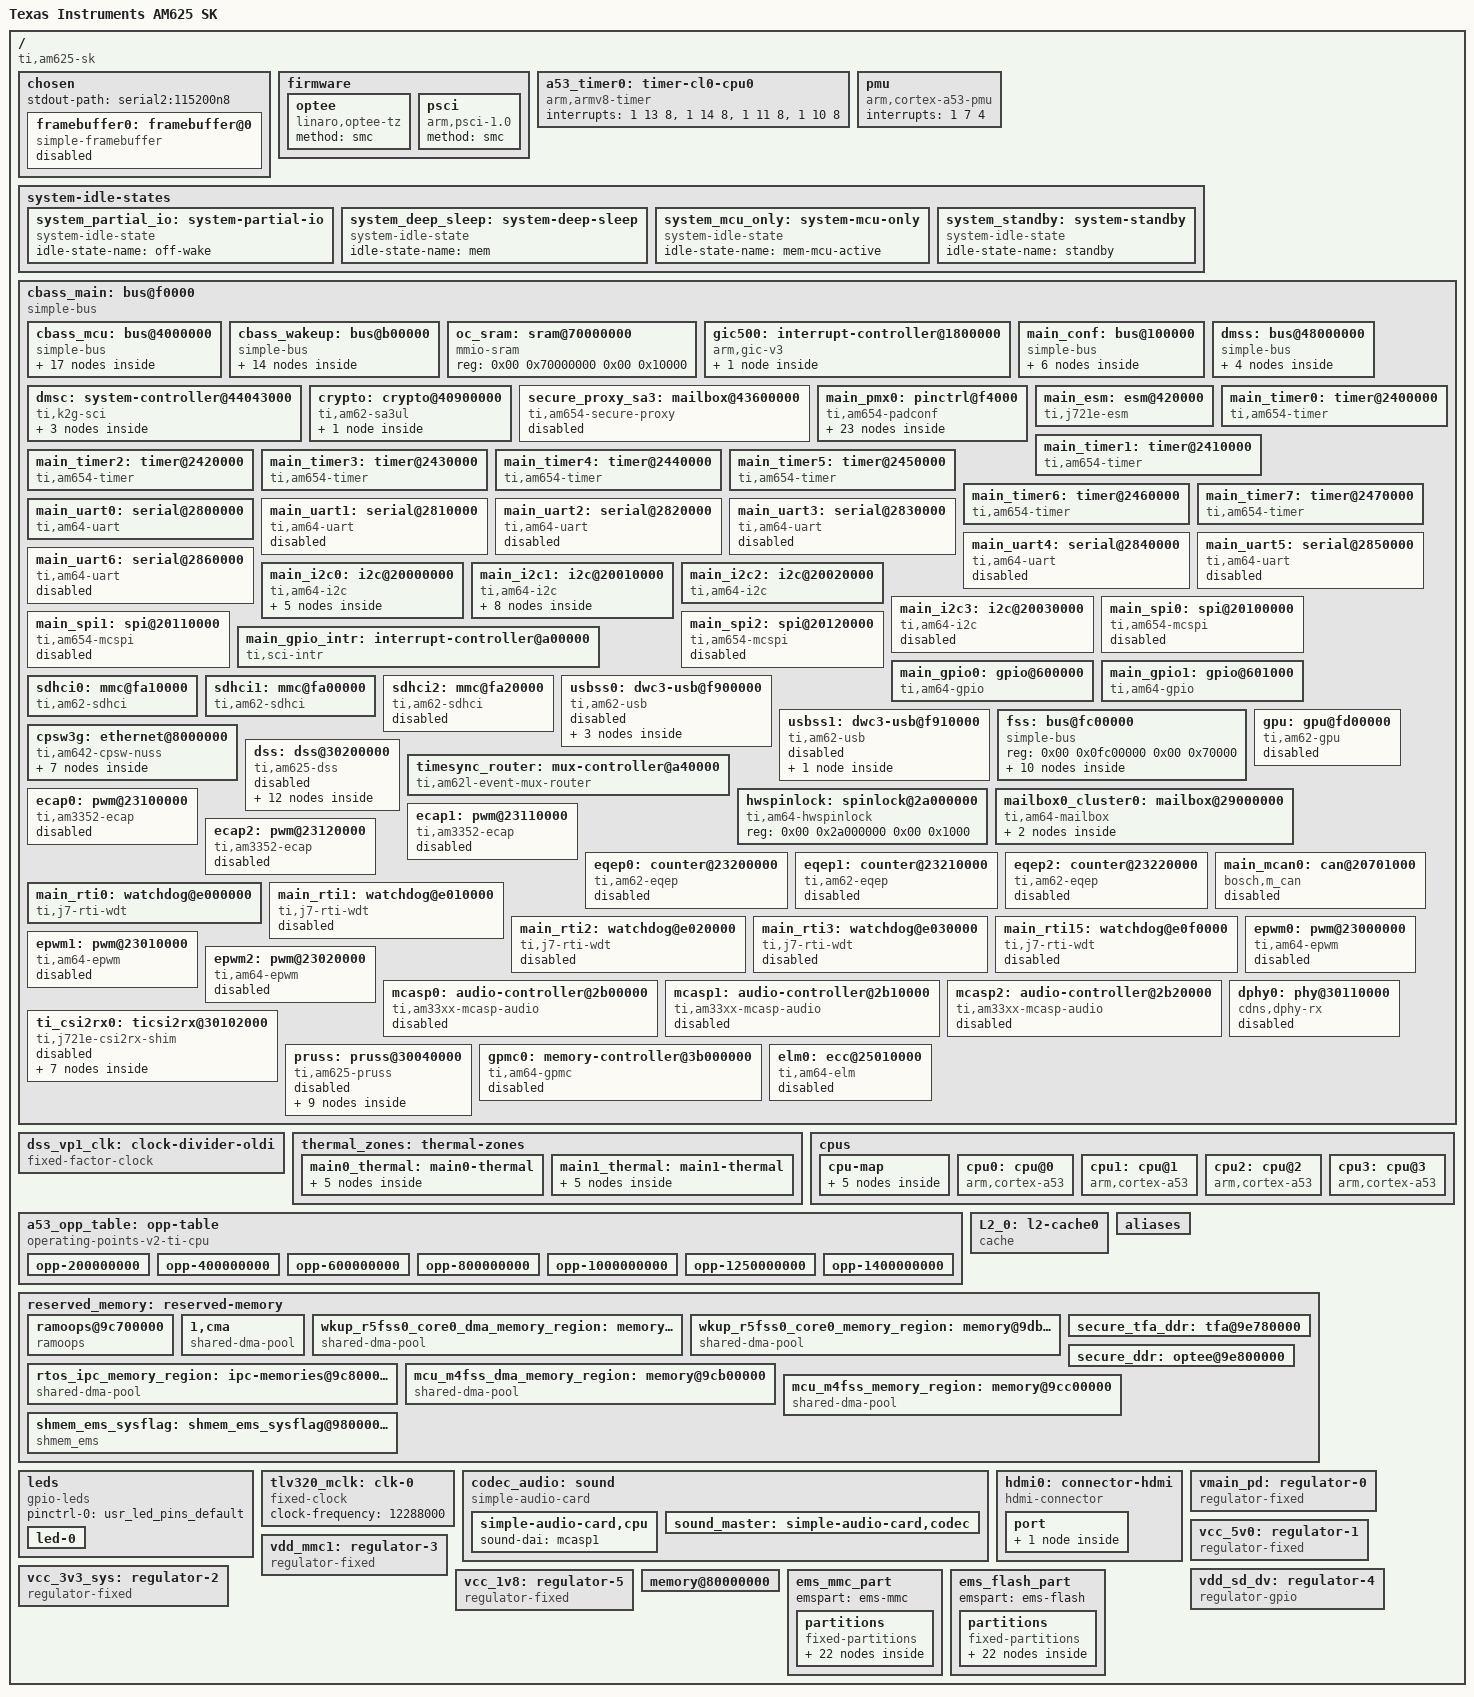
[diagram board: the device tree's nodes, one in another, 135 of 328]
/dts-v1/;
/dts-v1/;
/ {
 model = "Texas Instruments K3 AM625 SoC";
 compatible = "ti,am625";
 interrupt-parent = <&gic500>;
 #address-cells = <2>;
 #size-cells = <2>;
 chosen { };
 firmware {
  optee {
   compatible = "linaro,optee-tz";
   method = "smc";
  };
  psci: psci {
   compatible = "arm,psci-1.0";
   method = "smc";
  };
 };
 a53_timer0: timer-cl0-cpu0 {
  compatible = "arm,armv8-timer";
  interrupts = <1 13 8>,
        <1 14 8>,
        <1 11 8>,
        <1 10 8>;
 };
 pmu: pmu {
  compatible = "arm,cortex-a53-pmu";
  interrupts = <1 7 4>;
 };
 system-idle-states {
  system_partial_io: system-partial-io {
   compatible = "system-idle-state";
   idle-state-name = "off-wake";
  };
  system_deep_sleep: system-deep-sleep {
   compatible = "system-idle-state";
   idle-state-name = "mem";
  };
  system_mcu_only: system-mcu-only {
   compatible = "system-idle-state";
   idle-state-name = "mem-mcu-active";
  };
  system_standby: system-standby {
   compatible = "system-idle-state";
   idle-state-name = "standby";
  };
 };
 cbass_main: bus@f0000 {
  bootph-all;
  compatible = "simple-bus";
  #address-cells = <2>;
  #size-cells = <2>;
  ranges = <0x00 0x000f0000 0x00 0x000f0000 0x00 0x00030000>,
    <0x00 0x00420000 0x00 0x00420000 0x00 0x00001000>,
    <0x00 0x00600000 0x00 0x00600000 0x00 0x00001100>,
    <0x00 0x00703000 0x00 0x00703000 0x00 0x00000200>,
    <0x00 0x0070c000 0x00 0x0070c000 0x00 0x00000200>,
    <0x00 0x00a40000 0x00 0x00a40000 0x00 0x00000800>,
    <0x00 0x01000000 0x00 0x01000000 0x00 0x01b28400>,
    <0x00 0x08000000 0x00 0x08000000 0x00 0x00200000>,
    <0x00 0x0e000000 0x00 0x0e000000 0x00 0x01d20000>,
    <0x00 0x0fd00000 0x00 0x0fd00000 0x00 0x00020000>,
    <0x00 0x20000000 0x00 0x20000000 0x00 0x0a008000>,
    <0x00 0x30040000 0x00 0x30040000 0x00 0x00080000>,
    <0x00 0x30101000 0x00 0x30101000 0x00 0x00010100>,
    <0x00 0x30200000 0x00 0x30200000 0x00 0x00010000>,
    <0x00 0x31000000 0x00 0x31000000 0x00 0x00050000>,
    <0x00 0x31100000 0x00 0x31100000 0x00 0x00050000>,
    <0x00 0x3b000000 0x00 0x3b000000 0x00 0x00000400>,
    <0x00 0x40900000 0x00 0x40900000 0x00 0x00030000>,
    <0x00 0x43600000 0x00 0x43600000 0x00 0x00010000>,
    <0x00 0x44043000 0x00 0x44043000 0x00 0x00000fe0>,
    <0x00 0x44860000 0x00 0x44860000 0x00 0x00040000>,
    <0x00 0x48000000 0x00 0x48000000 0x00 0x06400000>,
    <0x00 0x50000000 0x00 0x50000000 0x00 0x08000000>,
    <0x00 0x60000000 0x00 0x60000000 0x00 0x08000000>,
    <0x00 0x70000000 0x00 0x70000000 0x00 0x00010000>,
    <0x01 0x00000000 0x01 0x00000000 0x00 0x00310000>,
    <0x05 0x00000000 0x05 0x00000000 0x01 0x00000000>,
    <0x00 0x04000000 0x00 0x04000000 0x00 0x01ff1400>,
    <0x00 0x00b00000 0x00 0x00b00000 0x00 0x00002400>,
    <0x00 0x2b000000 0x00 0x2b000000 0x00 0x00300400>,
    <0x00 0x43000000 0x00 0x43000000 0x00 0x00020000>,
    <0x00 0x78000000 0x00 0x78000000 0x00 0x00008000>,
    <0x00 0x78100000 0x00 0x78100000 0x00 0x00008000>;
  cbass_mcu: bus@4000000 {
   bootph-all;
   compatible = "simple-bus";
   #address-cells = <2>;
   #size-cells = <2>;
   ranges = <0x00 0x04000000 0x00 0x04000000 0x00 0x01ff1400>;
  };
  cbass_wakeup: bus@b00000 {
   bootph-all;
   compatible = "simple-bus";
   #address-cells = <2>;
   #size-cells = <2>;
   ranges = <0x00 0x00b00000 0x00 0x00b00000 0x00 0x00002400>,
     <0x00 0x2b000000 0x00 0x2b000000 0x00 0x00300400>,
     <0x00 0x43000000 0x00 0x43000000 0x00 0x00020000>,
     <0x00 0x78000000 0x00 0x78000000 0x00 0x00008000>,
     <0x00 0x78100000 0x00 0x78100000 0x00 0x00008000>;
  };
 };
 dss_vp1_clk: clock-divider-oldi {
  compatible = "fixed-factor-clock";
  clocks = <&k3_clks 186 0>;
  #clock-cells = <0>;
  clock-div = <7>;
  clock-mult = <1>;
 };
thermal_zones: thermal-zones {
 main0_thermal: main0-thermal {
  polling-delay-passive = <250>;
  polling-delay = <500>;
  thermal-sensors = <&wkup_vtm0 0>;
  trips {
   main0_alert: main0-alert {
    temperature = <95000>;
    hysteresis = <2000>;
    type = "passive";
   };
   main0_crit: main0-crit {
    temperature = <105000>;
    hysteresis = <2000>;
    type = "critical";
   };
  };
  cooling-maps {
   map0 {
    trip = <&main0_alert>;
    cooling-device =
     <&cpu0 (~0) (~0)>,
     <&cpu1 (~0) (~0)>,
     <&cpu2 (~0) (~0)>,
     <&cpu3 (~0) (~0)>;
   };
  };
 };
 main1_thermal: main1-thermal {
  polling-delay-passive = <250>;
  polling-delay = <500>;
  thermal-sensors = <&wkup_vtm0 1>;
  trips {
   main1_alert: main1-alert {
    temperature = <95000>;
    hysteresis = <2000>;
    type = "passive";
   };
   main1_crit: main1-crit {
    temperature = <105000>;
    hysteresis = <2000>;
    type = "critical";
   };
  };
  cooling-maps {
   map0 {
    trip = <&main1_alert>;
    cooling-device =
     <&cpu0 (~0) (~0)>,
     <&cpu1 (~0) (~0)>,
     <&cpu2 (~0) (~0)>,
     <&cpu3 (~0) (~0)>;
   };
  };
 };
};
};
&cbass_main {
 oc_sram: sram@70000000 {
  compatible = "mmio-sram";
  reg = <0x00 0x70000000 0x00 0x10000>;
  #address-cells = <1>;
  #size-cells = <1>;
  ranges = <0x0 0x00 0x70000000 0x10000>;
 };
 gic500: interrupt-controller@1800000 {
  compatible = "arm,gic-v3";
  #address-cells = <2>;
  #size-cells = <2>;
  ranges;
  #interrupt-cells = <3>;
  interrupt-controller;
  reg = <0x00 0x01800000 0x00 0x10000>,
        <0x00 0x01880000 0x00 0xc0000>,
        <0x01 0x00000000 0x00 0x2000>,
        <0x01 0x00010000 0x00 0x1000>,
        <0x01 0x00020000 0x00 0x2000>;
  interrupts = <1 9 4>;
  gic_its: msi-controller@1820000 {
   compatible = "arm,gic-v3-its";
   reg = <0x00 0x01820000 0x00 0x10000>;
   socionext,synquacer-pre-its = <0x1000000 0x400000>;
   msi-controller;
   #msi-cells = <1>;
  };
 };
 main_conf: bus@100000 {
  compatible = "simple-bus";
  #address-cells = <1>;
  #size-cells = <1>;
  ranges = <0x0 0x00 0x00100000 0x20000>;
  phy_gmii_sel: phy@4044 {
   compatible = "ti,am654-phy-gmii-sel";
   reg = <0x4044 0x8>;
   #phy-cells = <1>;
  };
  epwm_tbclk: clock-controller@4130 {
   compatible = "ti,am62-epwm-tbclk";
   reg = <0x4130 0x4>;
   #clock-cells = <1>;
  };
  audio_refclk0: clock-controller@82e0 {
   compatible = "ti,am62-audio-refclk";
   reg = <0x82e0 0x4>;
   clocks = <&k3_clks 157 0>;
   assigned-clocks = <&k3_clks 157 0>;
   assigned-clock-parents = <&k3_clks 157 8>;
   #clock-cells = <0>;
  };
  audio_refclk1: clock-controller@82e4 {
   compatible = "ti,am62-audio-refclk";
   reg = <0x82e4 0x4>;
   clocks = <&k3_clks 157 10>;
   assigned-clocks = <&k3_clks 157 10>;
   assigned-clock-parents = <&k3_clks 157 18>;
   #clock-cells = <0>;
  };
  dss_oldi_io_ctrl: oldi-io-controller@8600 {
   compatible = "ti,am625-dss-oldi-io-ctrl", "syscon";
   reg = <0x8600 0x200>;
  };
  dss_clk_ctrl: dss_clk_ctrl@8300 {
   compatible = "ti,am625-dss-clk-ctrl", "syscon";
   reg = <0x8300 0x4>;
  };
 };
 dmss: bus@48000000 {
  bootph-all;
  compatible = "simple-bus";
  #address-cells = <2>;
  #size-cells = <2>;
  dma-ranges;
  ranges = <0x00 0x48000000 0x00 0x48000000 0x00 0x06400000>;
  ti,sci-dev-id = <25>;
  secure_proxy_main: mailbox@4d000000 {
   bootph-all;
   compatible = "ti,am654-secure-proxy";
   #mbox-cells = <1>;
   reg-names = "target_data", "rt", "scfg";
   reg = <0x00 0x4d000000 0x00 0x80000>,
         <0x00 0x4a600000 0x00 0x80000>,
         <0x00 0x4a400000 0x00 0x80000>;
   interrupt-names = "rx_012";
   interrupts = <0 34 4>;
  };
  inta_main_dmss: interrupt-controller@48000000 {
   compatible = "ti,sci-inta";
   reg = <0x00 0x48000000 0x00 0x100000>;
   #interrupt-cells = <0>;
   interrupt-controller;
   interrupt-parent = <&gic500>;
   msi-controller;
   ti,sci = <&dmsc>;
   ti,sci-dev-id = <28>;
   ti,interrupt-ranges = <4 68 36>;
   ti,unmapped-event-sources = <&main_bcdma>, <&main_pktdma>;
  };
  main_bcdma: dma-controller@485c0100 {
   compatible = "ti,am64-dmss-bcdma";
   reg = <0x00 0x485c0100 0x00 0x100>,
         <0x00 0x4c000000 0x00 0x20000>,
         <0x00 0x4a820000 0x00 0x20000>,
         <0x00 0x4aa40000 0x00 0x20000>,
         <0x00 0x4bc00000 0x00 0x100000>,
         <0x00 0x48600000 0x00 0x8000>,
         <0x00 0x484a4000 0x00 0x2000>,
         <0x00 0x484c2000 0x00 0x2000>,
         <0x00 0x48420000 0x00 0x2000>;
   reg-names = "gcfg", "bchanrt", "rchanrt", "tchanrt", "ringrt",
        "ring", "tchan", "rchan", "bchan";
   msi-parent = <&inta_main_dmss>;
   #dma-cells = <3>;
   ti,sci = <&dmsc>;
   ti,sci-dev-id = <26>;
   ti,sci-rm-range-bchan = <0x20>;
   ti,sci-rm-range-rchan = <0x21>;
   ti,sci-rm-range-tchan = <0x22>;
  };
  main_pktdma: dma-controller@485c0000 {
   compatible = "ti,am64-dmss-pktdma";
   reg = <0x00 0x485c0000 0x00 0x100>,
         <0x00 0x4a800000 0x00 0x20000>,
         <0x00 0x4aa00000 0x00 0x20000>,
         <0x00 0x4b800000 0x00 0x200000>,
         <0x00 0x485e0000 0x00 0x10000>,
         <0x00 0x484a0000 0x00 0x2000>,
         <0x00 0x484c0000 0x00 0x2000>,
         <0x00 0x48430000 0x00 0x1000>;
   reg-names = "gcfg", "rchanrt", "tchanrt", "ringrt",
        "ring", "tchan", "rchan", "rflow";
   msi-parent = <&inta_main_dmss>;
   #dma-cells = <2>;
   ti,sci = <&dmsc>;
   ti,sci-dev-id = <30>;
   ti,sci-rm-range-tchan = <0x23>,
      <0x24>,
      <0x25>,
      <0x26>;
   ti,sci-rm-range-tflow = <0x10>,
      <0x11>,
      <0x12>,
      <0x13>;
   ti,sci-rm-range-rchan = <0x29>,
      <0x2b>,
      <0x2d>,
      <0x2f>,
      <0x31>,
      <0x33>;
   ti,sci-rm-range-rflow = <0x2a>,
      <0x2c>,
      <0x2e>,
      <0x32>;
  };
 };
 dmsc: system-controller@44043000 {
  bootph-all;
  compatible = "ti,k2g-sci";
  ti,host-id = <12>;
  mbox-names = "rx", "tx";
  mboxes = <&secure_proxy_main 12>,
    <&secure_proxy_main 13>;
  reg-names = "debug_messages";
  reg = <0x00 0x44043000 0x00 0xfe0>;
  k3_pds: power-controller {
   bootph-all;
   compatible = "ti,sci-pm-domain";
   #power-domain-cells = <2>;
  };
  k3_clks: clock-controller {
   bootph-all;
   compatible = "ti,k2g-sci-clk";
   #clock-cells = <2>;
  };
  k3_reset: reset-controller {
   bootph-all;
   compatible = "ti,sci-reset";
   #reset-cells = <2>;
  };
 };
 crypto: crypto@40900000 {
  compatible = "ti,am62-sa3ul";
  reg = <0x00 0x40900000 0x00 0x1200>;
  dmas = <&main_pktdma 0xf501 0>, <&main_pktdma 0x7506 0>,
         <&main_pktdma 0x7507 0>;
  dma-names = "tx", "rx1", "rx2";
  #address-cells = <2>;
  #size-cells = <2>;
  ranges = <0x00 0x40900000 0x00 0x40900000 0x00 0x30000>;
  rng: rng@40910000 {
   compatible = "inside-secure,safexcel-eip76";
   reg = <0x00 0x40910000 0x00 0x7d>;
   interrupts = <0 129 4>;
   status = "reserved";
  };
 };
 secure_proxy_sa3: mailbox@43600000 {
  bootph-pre-ram;
  compatible = "ti,am654-secure-proxy";
  #mbox-cells = <1>;
  reg-names = "target_data", "rt", "scfg";
  reg = <0x00 0x43600000 0x00 0x10000>,
        <0x00 0x44880000 0x00 0x20000>,
        <0x00 0x44860000 0x00 0x20000>;
  status = "disabled";
 };
 main_pmx0: pinctrl@f4000 {
  bootph-all;
  compatible = "ti,am654-padconf", "pinctrl-single";
  reg = <0x00 0xf4000 0x00 0x2ac>;
  #pinctrl-cells = <1>;
  pinctrl-single,register-width = <32>;
  pinctrl-single,function-mask = <0xffffffff>;
  interrupts = <0 98 4>;
  interrupt-controller;
  #interrupt-cells = <1>;
 };
 main_esm: esm@420000 {
  bootph-pre-ram;
  compatible = "ti,j721e-esm";
  reg = <0x00 0x420000 0x00 0x1000>;
  ti,esm-pins = <160>, <161>, <162>, <163>, <177>, <178>;
 };
 main_timer0: timer@2400000 {
  bootph-all;
  compatible = "ti,am654-timer";
  reg = <0x00 0x2400000 0x00 0x400>;
  interrupts = <0 120 4>;
  clocks = <&k3_clks 36 2>;
  clock-names = "fck";
  assigned-clocks = <&k3_clks 36 2>;
  assigned-clock-parents = <&k3_clks 36 3>;
  power-domains = <&k3_pds 36 1>;
  ti,timer-pwm;
 };
 main_timer1: timer@2410000 {
  compatible = "ti,am654-timer";
  reg = <0x00 0x2410000 0x00 0x400>;
  interrupts = <0 121 4>;
  clocks = <&k3_clks 37 2>;
  clock-names = "fck";
  assigned-clocks = <&k3_clks 37 2>;
  assigned-clock-parents = <&k3_clks 37 3>;
  power-domains = <&k3_pds 37 1>;
  ti,timer-pwm;
 };
 main_timer2: timer@2420000 {
  compatible = "ti,am654-timer";
  reg = <0x00 0x2420000 0x00 0x400>;
  interrupts = <0 122 4>;
  clocks = <&k3_clks 38 2>;
  clock-names = "fck";
  assigned-clocks = <&k3_clks 38 2>;
  assigned-clock-parents = <&k3_clks 38 3>;
  power-domains = <&k3_pds 38 1>;
  ti,timer-pwm;
 };
 main_timer3: timer@2430000 {
  compatible = "ti,am654-timer";
  reg = <0x00 0x2430000 0x00 0x400>;
  interrupts = <0 123 4>;
  clocks = <&k3_clks 39 2>;
  clock-names = "fck";
  assigned-clocks = <&k3_clks 39 2>;
  assigned-clock-parents = <&k3_clks 39 3>;
  power-domains = <&k3_pds 39 1>;
  ti,timer-pwm;
 };
 main_timer4: timer@2440000 {
  compatible = "ti,am654-timer";
  reg = <0x00 0x2440000 0x00 0x400>;
  interrupts = <0 124 4>;
  clocks = <&k3_clks 40 2>;
  clock-names = "fck";
  assigned-clocks = <&k3_clks 40 2>;
  assigned-clock-parents = <&k3_clks 40 3>;
  power-domains = <&k3_pds 40 1>;
  ti,timer-pwm;
 };
 main_timer5: timer@2450000 {
  compatible = "ti,am654-timer";
  reg = <0x00 0x2450000 0x00 0x400>;
  interrupts = <0 125 4>;
  clocks = <&k3_clks 41 2>;
  clock-names = "fck";
  assigned-clocks = <&k3_clks 41 2>;
  assigned-clock-parents = <&k3_clks 41 3>;
  power-domains = <&k3_pds 41 1>;
  ti,timer-pwm;
 };
 main_timer6: timer@2460000 {
  compatible = "ti,am654-timer";
  reg = <0x00 0x2460000 0x00 0x400>;
  interrupts = <0 126 4>;
  clocks = <&k3_clks 42 2>;
  clock-names = "fck";
  assigned-clocks = <&k3_clks 42 2>;
  assigned-clock-parents = <&k3_clks 42 3>;
  power-domains = <&k3_pds 42 1>;
  ti,timer-pwm;
 };
 main_timer7: timer@2470000 {
  compatible = "ti,am654-timer";
  reg = <0x00 0x2470000 0x00 0x400>;
  interrupts = <0 127 4>;
  clocks = <&k3_clks 43 2>;
  clock-names = "fck";
  assigned-clocks = <&k3_clks 43 2>;
  assigned-clock-parents = <&k3_clks 43 3>;
  power-domains = <&k3_pds 43 1>;
  ti,timer-pwm;
 };
 main_uart0: serial@2800000 {
  compatible = "ti,am64-uart", "ti,am654-uart";
  reg = <0x00 0x02800000 0x00 0x100>;
  interrupts = <0 178 4>;
  power-domains = <&k3_pds 146 1>;
  clocks = <&k3_clks 146 0>;
  clock-names = "fclk";
  status = "disabled";
 };
 main_uart1: serial@2810000 {
  compatible = "ti,am64-uart", "ti,am654-uart";
  reg = <0x00 0x02810000 0x00 0x100>;
  interrupts = <0 179 4>;
  power-domains = <&k3_pds 152 1>;
  clocks = <&k3_clks 152 0>;
  clock-names = "fclk";
  status = "disabled";
 };
 main_uart2: serial@2820000 {
  compatible = "ti,am64-uart", "ti,am654-uart";
  reg = <0x00 0x02820000 0x00 0x100>;
  interrupts = <0 180 4>;
  power-domains = <&k3_pds 153 1>;
  clocks = <&k3_clks 153 0>;
  clock-names = "fclk";
  status = "disabled";
 };
 main_uart3: serial@2830000 {
  compatible = "ti,am64-uart", "ti,am654-uart";
  reg = <0x00 0x02830000 0x00 0x100>;
  interrupts = <0 181 4>;
  power-domains = <&k3_pds 154 1>;
  clocks = <&k3_clks 154 0>;
  clock-names = "fclk";
  status = "disabled";
 };
 main_uart4: serial@2840000 {
  compatible = "ti,am64-uart", "ti,am654-uart";
  reg = <0x00 0x02840000 0x00 0x100>;
  interrupts = <0 182 4>;
  power-domains = <&k3_pds 155 1>;
  clocks = <&k3_clks 155 0>;
  clock-names = "fclk";
  status = "disabled";
 };
 main_uart5: serial@2850000 {
  compatible = "ti,am64-uart", "ti,am654-uart";
  reg = <0x00 0x02850000 0x00 0x100>;
  interrupts = <0 183 4>;
  power-domains = <&k3_pds 156 1>;
  clocks = <&k3_clks 156 0>;
  clock-names = "fclk";
  status = "disabled";
 };
 main_uart6: serial@2860000 {
  compatible = "ti,am64-uart", "ti,am654-uart";
  reg = <0x00 0x02860000 0x00 0x100>;
  interrupts = <0 184 4>;
  power-domains = <&k3_pds 158 1>;
  clocks = <&k3_clks 158 0>;
  clock-names = "fclk";
  status = "disabled";
 };
 main_i2c0: i2c@20000000 {
  compatible = "ti,am64-i2c", "ti,omap4-i2c";
  reg = <0x00 0x20000000 0x00 0x100>;
  interrupts = <0 161 4>;
  #address-cells = <1>;
  #size-cells = <0>;
  power-domains = <&k3_pds 102 1>;
  clocks = <&k3_clks 102 2>;
  clock-names = "fck";
  status = "disabled";
 };
 main_i2c1: i2c@20010000 {
  compatible = "ti,am64-i2c", "ti,omap4-i2c";
  reg = <0x00 0x20010000 0x00 0x100>;
  interrupts = <0 162 4>;
  #address-cells = <1>;
  #size-cells = <0>;
  power-domains = <&k3_pds 103 1>;
  clocks = <&k3_clks 103 2>;
  clock-names = "fck";
  status = "disabled";
 };
 main_i2c2: i2c@20020000 {
  compatible = "ti,am64-i2c", "ti,omap4-i2c";
  reg = <0x00 0x20020000 0x00 0x100>;
  interrupts = <0 163 4>;
  #address-cells = <1>;
  #size-cells = <0>;
  power-domains = <&k3_pds 104 1>;
  clocks = <&k3_clks 104 2>;
  clock-names = "fck";
  status = "disabled";
 };
 main_i2c3: i2c@20030000 {
  compatible = "ti,am64-i2c", "ti,omap4-i2c";
  reg = <0x00 0x20030000 0x00 0x100>;
  interrupts = <0 164 4>;
  #address-cells = <1>;
  #size-cells = <0>;
  power-domains = <&k3_pds 105 1>;
  clocks = <&k3_clks 105 2>;
  clock-names = "fck";
  status = "disabled";
 };
 main_spi0: spi@20100000 {
  compatible = "ti,am654-mcspi", "ti,omap4-mcspi";
  reg = <0x00 0x20100000 0x00 0x400>;
  interrupts = <0 172 4>;
  #address-cells = <1>;
  #size-cells = <0>;
  power-domains = <&k3_pds 141 1>;
  clocks = <&k3_clks 141 0>;
  status = "disabled";
 };
 main_spi1: spi@20110000 {
  compatible = "ti,am654-mcspi","ti,omap4-mcspi";
  reg = <0x00 0x20110000 0x00 0x400>;
  interrupts = <0 173 4>;
  #address-cells = <1>;
  #size-cells = <0>;
  power-domains = <&k3_pds 142 1>;
  clocks = <&k3_clks 142 0>;
  status = "disabled";
 };
 main_spi2: spi@20120000 {
  compatible = "ti,am654-mcspi","ti,omap4-mcspi";
  reg = <0x00 0x20120000 0x00 0x400>;
  interrupts = <0 174 4>;
  #address-cells = <1>;
  #size-cells = <0>;
  power-domains = <&k3_pds 143 1>;
  clocks = <&k3_clks 143 0>;
  status = "disabled";
 };
 main_gpio_intr: interrupt-controller@a00000 {
  compatible = "ti,sci-intr";
  reg = <0x00 0x00a00000 0x00 0x800>;
  ti,intr-trigger-type = <1>;
  interrupt-controller;
  interrupt-parent = <&gic500>;
  #interrupt-cells = <1>;
  ti,sci = <&dmsc>;
  ti,sci-dev-id = <3>;
  ti,interrupt-ranges = <0 32 16>;
 };
 main_gpio0: gpio@600000 {
  compatible = "ti,am64-gpio", "ti,keystone-gpio";
  reg = <0x0 0x00600000 0x0 0x100>;
  gpio-ranges = <&main_pmx0 0 0 32>,
         <&main_pmx0 32 33 38>,
         <&main_pmx0 70 72 22>;
  gpio-controller;
  #gpio-cells = <2>;
  interrupt-parent = <&main_gpio_intr>;
  interrupts = <190>, <191>, <192>,
        <193>, <194>, <195>;
  interrupt-controller;
  #interrupt-cells = <2>;
  ti,ngpio = <92>;
  ti,davinci-gpio-unbanked = <0>;
  power-domains = <&k3_pds 77 1>;
  clocks = <&k3_clks 77 0>;
  clock-names = "gpio";
 };
 main_gpio1: gpio@601000 {
  compatible = "ti,am64-gpio", "ti,keystone-gpio";
  reg = <0x0 0x00601000 0x0 0x100>;
  gpio-controller;
  gpio-ranges = <&main_pmx0 0 94 41>,
         <&main_pmx0 41 136 6>,
         <&main_pmx0 47 143 3>,
         <&main_pmx0 50 149 2>;
  #gpio-cells = <2>;
  interrupt-parent = <&main_gpio_intr>;
  interrupts = <180>, <181>, <182>,
        <183>, <184>, <185>;
  interrupt-controller;
  #interrupt-cells = <2>;
  ti,ngpio = <52>;
  ti,davinci-gpio-unbanked = <0>;
  power-domains = <&k3_pds 78 1>;
  clocks = <&k3_clks 78 0>;
  clock-names = "gpio";
 };
 sdhci0: mmc@fa10000 {
  compatible = "ti,am62-sdhci";
  reg = <0x00 0x0fa10000 0x00 0x1000>, <0x00 0x0fa18000 0x00 0x400>;
  interrupts = <0 133 4>;
  power-domains = <&k3_pds 57 1>;
  clocks = <&k3_clks 57 5>, <&k3_clks 57 6>;
  clock-names = "clk_ahb", "clk_xin";
  bus-width = <8>;
  mmc-hs200-1_8v;
  ti,clkbuf-sel = <0x7>;
  ti,otap-del-sel-legacy = <0x0>;
  ti,otap-del-sel-mmc-hs = <0x0>;
  ti,otap-del-sel-hs200 = <0x6>;
  ti,itap-del-sel-legacy = <0x0>;
  ti,itap-del-sel-mmc-hs = <0x0>;
  status = "disabled";
 };
 sdhci1: mmc@fa00000 {
  compatible = "ti,am62-sdhci";
  reg = <0x00 0x0fa00000 0x00 0x1000>, <0x00 0x0fa08000 0x00 0x400>;
  interrupts = <0 83 4>;
  power-domains = <&k3_pds 58 1>;
  clocks = <&k3_clks 58 5>, <&k3_clks 58 6>;
  clock-names = "clk_ahb", "clk_xin";
  bus-width = <4>;
  ti,clkbuf-sel = <0x7>;
  ti,otap-del-sel-legacy = <0x0>;
  ti,otap-del-sel-sd-hs = <0x0>;
  ti,otap-del-sel-sdr12 = <0xf>;
  ti,otap-del-sel-sdr25 = <0xf>;
  ti,otap-del-sel-sdr50 = <0xc>;
  ti,otap-del-sel-sdr104 = <0x6>;
  ti,otap-del-sel-ddr50 = <0x9>;
  ti,itap-del-sel-legacy = <0x0>;
  ti,itap-del-sel-sd-hs = <0x0>;
  ti,itap-del-sel-sdr12 = <0x0>;
  ti,itap-del-sel-sdr25 = <0x0>;
  status = "disabled";
 };
 sdhci2: mmc@fa20000 {
  compatible = "ti,am62-sdhci";
  reg = <0x00 0x0fa20000 0x00 0x1000>, <0x00 0x0fa28000 0x00 0x400>;
  interrupts = <0 82 4>;
  power-domains = <&k3_pds 184 1>;
  clocks = <&k3_clks 184 5>, <&k3_clks 184 6>;
  clock-names = "clk_ahb", "clk_xin";
  bus-width = <4>;
  ti,clkbuf-sel = <0x7>;
  ti,otap-del-sel-legacy = <0x0>;
  ti,otap-del-sel-sd-hs = <0x0>;
  ti,otap-del-sel-sdr12 = <0xf>;
  ti,otap-del-sel-sdr25 = <0xf>;
  ti,otap-del-sel-sdr50 = <0xc>;
  ti,otap-del-sel-sdr104 = <0x6>;
  ti,otap-del-sel-ddr50 = <0x9>;
  ti,itap-del-sel-legacy = <0x0>;
  ti,itap-del-sel-sd-hs = <0x0>;
  ti,itap-del-sel-sdr12 = <0x0>;
  ti,itap-del-sel-sdr25 = <0x0>;
  status = "disabled";
 };
 usbss0: dwc3-usb@f900000 {
  compatible = "ti,am62-usb";
  reg = <0x00 0x0f900000 0x00 0x800>,
        <0x00 0x0f908000 0x00 0x400>;
  clocks = <&k3_clks 161 3>;
  clock-names = "ref";
  ti,syscon-phy-pll-refclk = <&usb0_phy_ctrl 0x0>;
  #address-cells = <2>;
  #size-cells = <2>;
  power-domains = <&k3_pds 178 1>;
  ranges;
  status = "disabled";
  usb0: usb@31000000 {
   compatible = "snps,dwc3";
   reg = <0x00 0x31000000 0x00 0x50000>;
   interrupts = <0 188 4>,
         <0 188 4>;
   interrupt-names = "host", "peripheral";
   maximum-speed = "high-speed";
   dr_mode = "otg";
   snps,usb2-gadget-lpm-disable;
   snps,usb2-lpm-disable;
  };
 };
 usbss1: dwc3-usb@f910000 {
  compatible = "ti,am62-usb";
  reg = <0x00 0x0f910000 0x00 0x800>,
        <0x00 0x0f918000 0x00 0x400>;
  clocks = <&k3_clks 162 3>;
  clock-names = "ref";
  ti,syscon-phy-pll-refclk = <&usb1_phy_ctrl 0x0>;
  #address-cells = <2>;
  #size-cells = <2>;
  power-domains = <&k3_pds 179 1>;
  ranges;
  status = "disabled";
  usb1: usb@31100000 {
   compatible = "snps,dwc3";
   reg = <0x00 0x31100000 0x00 0x50000>;
   interrupts = <0 226 4>,
         <0 226 4>;
   interrupt-names = "host", "peripheral";
   maximum-speed = "high-speed";
   dr_mode = "otg";
   snps,usb2-gadget-lpm-disable;
   snps,usb2-lpm-disable;
  };
 };
 fss: bus@fc00000 {
  compatible = "simple-bus";
  reg = <0x00 0x0fc00000 0x00 0x70000>;
  #address-cells = <2>;
  #size-cells = <2>;
  ranges;
  ospi0: spi@fc40000 {
   compatible = "ti,am654-ospi", "cdns,qspi-nor";
   reg = <0x00 0x0fc40000 0x00 0x100>,
         <0x05 0x00000000 0x01 0x00000000>;
   interrupts = <0 139 4>;
   cdns,fifo-depth = <256>;
   cdns,fifo-width = <4>;
   cdns,trigger-address = <0x0>;
   cdns,phase-detect-selector = <2>;
   clocks = <&k3_clks 75 7>;
   assigned-clocks = <&k3_clks 75 7>;
   assigned-clock-parents = <&k3_clks 75 8>;
   assigned-clock-rates = <166666666>;
   power-domains = <&k3_pds 75 1>;
   #address-cells = <1>;
   #size-cells = <0>;
   status = "disabled";
  };
 };
 gpu: gpu@fd00000 {
  compatible = "ti,am62-gpu", "img,img-axe-1-16m", "img,img-axe",
        "img,img-rogue";
  reg = <0x00 0x0fd00000 0x00 0x20000>;
  clocks = <&k3_clks 187 0>;
  clock-names = "core";
  interrupts = <0 86 4>;
  power-domains = <&k3_pds 187 1>;
  power-domain-names = "a";
 };
 cpsw3g: ethernet@8000000 {
  compatible = "ti,am642-cpsw-nuss";
  #address-cells = <2>;
  #size-cells = <2>;
  reg = <0x00 0x08000000 0x00 0x200000>;
  reg-names = "cpsw_nuss";
  ranges = <0x00 0x00 0x00 0x08000000 0x00 0x200000>;
  clocks = <&k3_clks 13 0>;
  assigned-clocks = <&k3_clks 13 3>;
  assigned-clock-parents = <&k3_clks 13 11>;
  clock-names = "fck";
  power-domains = <&k3_pds 13 1>;
  dmas = <&main_pktdma 0xc600 15>,
         <&main_pktdma 0xc601 15>,
         <&main_pktdma 0xc602 15>,
         <&main_pktdma 0xc603 15>,
         <&main_pktdma 0xc604 15>,
         <&main_pktdma 0xc605 15>,
         <&main_pktdma 0xc606 15>,
         <&main_pktdma 0xc607 15>,
         <&main_pktdma 0x4600 15>;
  dma-names = "tx0", "tx1", "tx2", "tx3", "tx4", "tx5", "tx6",
       "tx7", "rx";
  ethernet-ports {
   #address-cells = <1>;
   #size-cells = <0>;
   cpsw_port1: port@1 {
    reg = <1>;
    ti,mac-only;
    label = "port1";
    phys = <&phy_gmii_sel 1>;
    mac-address = [00 00 00 00 00 00];
    ti,syscon-efuse = <&cpsw_mac_syscon 0x0>;
   };
   cpsw_port2: port@2 {
    reg = <2>;
    ti,mac-only;
    label = "port2";
    phys = <&phy_gmii_sel 2>;
    mac-address = [00 00 00 00 00 00];
   };
  };
  cpsw3g_mdio: mdio@f00 {
   compatible = "ti,cpsw-mdio","ti,davinci_mdio";
   reg = <0x00 0xf00 0x00 0x100>;
   #address-cells = <1>;
   #size-cells = <0>;
   clocks = <&k3_clks 13 0>;
   clock-names = "fck";
   bus_freq = <1000000>;
   status = "disabled";
  };
  cpts@3d000 {
   compatible = "ti,j721e-cpts";
   reg = <0x00 0x3d000 0x00 0x400>;
   clocks = <&k3_clks 13 3>;
   clock-names = "cpts";
   interrupts-extended = <&gic500 0 102 4>;
   interrupt-names = "cpts";
   ti,cpts-ext-ts-inputs = <4>;
   ti,cpts-periodic-outputs = <2>;
  };
 };
 dss: dss@30200000 {
  compatible = "ti,am625-dss";
  reg = <0x00 0x30200000 0x00 0x1000>,
        <0x00 0x30202000 0x00 0x1000>,
        <0x00 0x30206000 0x00 0x1000>,
        <0x00 0x30207000 0x00 0x1000>,
        <0x00 0x30208000 0x00 0x1000>,
        <0x00 0x3020a000 0x00 0x1000>,
        <0x00 0x3020b000 0x00 0x1000>,
        <0x00 0x30201000 0x00 0x1000>;
  reg-names = "common", "vidl1", "vid",
       "ovr1", "ovr2", "vp1", "vp2", "common1";
  power-domains = <&k3_pds 186 1>;
  clocks = <&k3_clks 186 6>,
    <&dss_vp1_clk>,
    <&k3_clks 186 2>;
  clock-names = "fck", "vp1", "vp2";
  interrupts = <0 84 4>;
  ti,clk-ctrl = <&dss_clk_ctrl>;
  status = "disabled";
  oldi-transmitters {
   #address-cells = <1>;
   #size-cells = <0>;
   oldi0: oldi@0 {
    reg = <0>;
    clocks = <&k3_clks 186 0>;
    clock-names = "serial";
    ti,oldi-io-ctrl = <&dss_oldi_io_ctrl>;
    status = "disabled";
    ports {
     #address-cells = <1>;
     #size-cells = <0>;
     oldi0_port0: port@0 {
      reg = <0>;
     };
     oldi0_port1: port@1 {
      reg = <1>;
     };
    };
   };
   oldi1: oldi@1 {
    reg = <1>;
    clocks = <&k3_clks 186 0>;
    clock-names = "serial";
    ti,oldi-io-ctrl = <&dss_oldi_io_ctrl>;
    status = "disabled";
    ports {
     #address-cells = <1>;
     #size-cells = <0>;
     oldi1_port0: port@0 {
      reg = <0>;
     };
     oldi1_port1: port@1 {
      reg = <1>;
     };
    };
   };
  };
  dss_ports: ports {
   #address-cells = <1>;
   #size-cells = <0>;
  };
 };
 timesync_router: mux-controller@a40000 {
  compatible = "ti,am62l-event-mux-router";
  reg = <0x0 0xa40000 0x0 0x800>;
  #mux-control-cells = <1>;
  status = "disabled";
 };
 hwspinlock: spinlock@2a000000 {
  compatible = "ti,am64-hwspinlock";
  reg = <0x00 0x2a000000 0x00 0x1000>;
  #hwlock-cells = <1>;
 };
 mailbox0_cluster0: mailbox@29000000 {
  compatible = "ti,am64-mailbox";
  reg = <0x00 0x29000000 0x00 0x200>;
  interrupts = <0 76 4>,
        <0 77 4>;
  #mbox-cells = <1>;
  ti,mbox-num-users = <4>;
  ti,mbox-num-fifos = <16>;
  status = "disabled";
 };
 ecap0: pwm@23100000 {
  compatible = "ti,am3352-ecap";
  #pwm-cells = <3>;
  reg = <0x00 0x23100000 0x00 0x100>;
  power-domains = <&k3_pds 51 1>;
  clocks = <&k3_clks 51 0>;
  clock-names = "fck";
  status = "disabled";
 };
 ecap1: pwm@23110000 {
  compatible = "ti,am3352-ecap";
  #pwm-cells = <3>;
  reg = <0x00 0x23110000 0x00 0x100>;
  power-domains = <&k3_pds 52 1>;
  clocks = <&k3_clks 52 0>;
  clock-names = "fck";
  status = "disabled";
 };
 ecap2: pwm@23120000 {
  compatible = "ti,am3352-ecap";
  #pwm-cells = <3>;
  reg = <0x00 0x23120000 0x00 0x100>;
  power-domains = <&k3_pds 53 1>;
  clocks = <&k3_clks 53 0>;
  clock-names = "fck";
  status = "disabled";
 };
 eqep0: counter@23200000 {
  compatible = "ti,am62-eqep";
  reg = <0x00 0x23200000 0x00 0x100>;
  power-domains = <&k3_pds 59 1>;
  clocks = <&k3_clks 59 0>;
  interrupts = <0 116 1>;
  status = "disabled";
 };
 eqep1: counter@23210000 {
  compatible = "ti,am62-eqep";
  reg = <0x00 0x23210000 0x00 0x100>;
  power-domains = <&k3_pds 60 1>;
  clocks = <&k3_clks 60 0>;
  interrupts = <0 117 1>;
  status = "disabled";
 };
 eqep2: counter@23220000 {
  compatible = "ti,am62-eqep";
  reg = <0x00 0x23220000 0x00 0x100>;
  power-domains = <&k3_pds 62 1>;
  clocks = <&k3_clks 62 0>;
  interrupts = <0 118 1>;
  status = "disabled";
 };
 main_mcan0: can@20701000 {
  compatible = "bosch,m_can";
  reg = <0x00 0x20701000 0x00 0x200>,
        <0x00 0x20708000 0x00 0x8000>;
  reg-names = "m_can", "message_ram";
  power-domains = <&k3_pds 98 1>;
  clocks = <&k3_clks 98 6>, <&k3_clks 98 1>;
  clock-names = "hclk", "cclk";
  interrupts = <0 155 4>,
        <0 156 4>;
  interrupt-names = "int0", "int1";
  bosch,mram-cfg = <0x0 128 64 64 64 64 32 32>;
  status = "disabled";
 };
 main_rti0: watchdog@e000000 {
  compatible = "ti,j7-rti-wdt";
  reg = <0x00 0x0e000000 0x00 0x100>;
  clocks = <&k3_clks 125 0>;
  power-domains = <&k3_pds 125 1>;
  assigned-clocks = <&k3_clks 125 0>;
  assigned-clock-parents = <&k3_clks 125 2>;
 };
 main_rti1: watchdog@e010000 {
  compatible = "ti,j7-rti-wdt";
  reg = <0x00 0x0e010000 0x00 0x100>;
  clocks = <&k3_clks 126 0>;
  power-domains = <&k3_pds 126 1>;
  assigned-clocks = <&k3_clks 126 0>;
  assigned-clock-parents = <&k3_clks 126 2>;
 };
 main_rti2: watchdog@e020000 {
  compatible = "ti,j7-rti-wdt";
  reg = <0x00 0x0e020000 0x00 0x100>;
  clocks = <&k3_clks 127 0>;
  power-domains = <&k3_pds 127 1>;
  assigned-clocks = <&k3_clks 127 0>;
  assigned-clock-parents = <&k3_clks 127 2>;
 };
 main_rti3: watchdog@e030000 {
  compatible = "ti,j7-rti-wdt";
  reg = <0x00 0x0e030000 0x00 0x100>;
  clocks = <&k3_clks 128 0>;
  power-domains = <&k3_pds 128 1>;
  assigned-clocks = <&k3_clks 128 0>;
  assigned-clock-parents = <&k3_clks 128 2>;
 };
 main_rti15: watchdog@e0f0000 {
  compatible = "ti,j7-rti-wdt";
  reg = <0x00 0x0e0f0000 0x00 0x100>;
  clocks = <&k3_clks 130 0>;
  power-domains = <&k3_pds 130 1>;
  assigned-clocks = <&k3_clks 130 0>;
  assigned-clock-parents = <&k3_clks 130 2>;
 };
 epwm0: pwm@23000000 {
  compatible = "ti,am64-epwm", "ti,am3352-ehrpwm";
  #pwm-cells = <3>;
  reg = <0x00 0x23000000 0x00 0x100>;
  power-domains = <&k3_pds 86 1>;
  clocks = <&epwm_tbclk 0>, <&k3_clks 86 0>;
  clock-names = "tbclk", "fck";
  status = "disabled";
 };
 epwm1: pwm@23010000 {
  compatible = "ti,am64-epwm", "ti,am3352-ehrpwm";
  #pwm-cells = <3>;
  reg = <0x00 0x23010000 0x00 0x100>;
  power-domains = <&k3_pds 87 1>;
  clocks = <&epwm_tbclk 1>, <&k3_clks 87 0>;
  clock-names = "tbclk", "fck";
  status = "disabled";
 };
 epwm2: pwm@23020000 {
  compatible = "ti,am64-epwm", "ti,am3352-ehrpwm";
  #pwm-cells = <3>;
  reg = <0x00 0x23020000 0x00 0x100>;
  power-domains = <&k3_pds 88 1>;
  clocks = <&epwm_tbclk 2>, <&k3_clks 88 0>;
  clock-names = "tbclk", "fck";
  status = "disabled";
 };
 mcasp0: audio-controller@2b00000 {
  compatible = "ti,am33xx-mcasp-audio";
  reg = <0x00 0x02b00000 0x00 0x2000>,
        <0x00 0x02b08000 0x00 0x400>;
  reg-names = "mpu", "dat";
  interrupts = <0 236 4>,
        <0 235 4>;
  interrupt-names = "tx", "rx";
  dmas = <&main_bcdma 0 0xc500 0>, <&main_bcdma 0 0x4500 0>;
  dma-names = "tx", "rx";
  clocks = <&k3_clks 190 0>;
  clock-names = "fck";
  assigned-clocks = <&k3_clks 190 0>;
  assigned-clock-parents = <&k3_clks 190 2>;
  power-domains = <&k3_pds 190 1>;
  status = "disabled";
 };
 mcasp1: audio-controller@2b10000 {
  compatible = "ti,am33xx-mcasp-audio";
  reg = <0x00 0x02b10000 0x00 0x2000>,
        <0x00 0x02b18000 0x00 0x400>;
  reg-names = "mpu", "dat";
  interrupts = <0 238 4>,
        <0 237 4>;
  interrupt-names = "tx", "rx";
  dmas = <&main_bcdma 0 0xc501 0>, <&main_bcdma 0 0x4501 0>;
  dma-names = "tx", "rx";
  clocks = <&k3_clks 191 0>;
  clock-names = "fck";
  assigned-clocks = <&k3_clks 191 0>;
  assigned-clock-parents = <&k3_clks 191 2>;
  power-domains = <&k3_pds 191 1>;
  status = "disabled";
 };
 mcasp2: audio-controller@2b20000 {
  compatible = "ti,am33xx-mcasp-audio";
  reg = <0x00 0x02b20000 0x00 0x2000>,
        <0x00 0x02b28000 0x00 0x400>;
  reg-names = "mpu", "dat";
  interrupts = <0 240 4>,
        <0 239 4>;
  interrupt-names = "tx", "rx";
  dmas = <&main_bcdma 0 0xc502 0>, <&main_bcdma 0 0x4502 0>;
  dma-names = "tx", "rx";
  clocks = <&k3_clks 192 0>;
  clock-names = "fck";
  assigned-clocks = <&k3_clks 192 0>;
  assigned-clock-parents = <&k3_clks 192 2>;
  power-domains = <&k3_pds 192 1>;
  status = "disabled";
 };
 ti_csi2rx0: ticsi2rx@30102000 {
  compatible = "ti,j721e-csi2rx-shim";
  dmas = <&main_bcdma 0 0x4700 0>, <&main_bcdma 0 0x4701 0>,
         <&main_bcdma 0 0x4702 0>, <&main_bcdma 0 0x4703 0>;
  dma-names = "rx0", "rx1", "rx2", "rx3";
  reg = <0x00 0x30102000 0x00 0x1000>;
  power-domains = <&k3_pds 182 1>;
  #address-cells = <2>;
  #size-cells = <2>;
  ranges;
  status = "disabled";
  cdns_csi2rx0: csi-bridge@30101000 {
   compatible = "ti,j721e-csi2rx", "cdns,csi2rx";
   reg = <0x00 0x30101000 0x00 0x1000>;
   interrupts = <0 143 4>,
         <0 141 4>;
   interrupt-names = "error_irq", "irq";
   clocks = <&k3_clks 182 0>, <&k3_clks 182 3>, <&k3_clks 182 0>,
    <&k3_clks 182 0>, <&k3_clks 182 4>, <&k3_clks 182 4>;
   clock-names = "sys_clk", "p_clk", "pixel_if0_clk",
    "pixel_if1_clk", "pixel_if2_clk", "pixel_if3_clk";
   phys = <&dphy0>;
   phy-names = "dphy";
   ports {
    #address-cells = <1>;
    #size-cells = <0>;
    csi0_port0: port@0 {
     reg = <0>;
     status = "disabled";
    };
    csi0_port1: port@1 {
     reg = <1>;
     status = "disabled";
    };
    csi0_port2: port@2 {
     reg = <2>;
     status = "disabled";
    };
    csi0_port3: port@3 {
     reg = <3>;
     status = "disabled";
    };
    csi0_port4: port@4 {
     reg = <4>;
     status = "disabled";
    };
   };
  };
 };
 dphy0: phy@30110000 {
  compatible = "cdns,dphy-rx";
  reg = <0x00 0x30110000 0x00 0x1100>;
  #phy-cells = <0>;
  power-domains = <&k3_pds 185 1>;
  status = "disabled";
 };
 pruss: pruss@30040000 {
  compatible = "ti,am625-pruss";
  reg = <0x00 0x30040000 0x00 0x80000>;
  power-domains = <&k3_pds 81 1>;
  #address-cells = <1>;
  #size-cells = <1>;
  ranges = <0x0 0x00 0x30040000 0x80000>;
  pruss_mem: memories@0 {
   reg = <0x0 0x2000>,
         <0x2000 0x2000>,
         <0x10000 0x10000>;
   reg-names = "dram0", "dram1", "shrdram2";
  };
  pruss_cfg: cfg@26000 {
   compatible = "ti,pruss-cfg", "syscon";
   reg = <0x26000 0x200>;
   #address-cells = <1>;
   #size-cells = <1>;
   ranges = <0x0 0x26000 0x2000>;
   clocks {
    #address-cells = <1>;
    #size-cells = <0>;
    pruss_coreclk_mux: coreclk-mux@3c {
     reg = <0x3c>;
     #clock-cells = <0>;
     clocks = <&k3_clks 81 0>,
       <&k3_clks 81 14>;
     assigned-clocks = <&pruss_coreclk_mux>;
     assigned-clock-parents = <&k3_clks 81 14>;
    };
    pruss_iepclk_mux: iepclk-mux@30 {
     reg = <0x30>;
     #clock-cells = <0>;
     clocks = <&k3_clks 81 3>,
       <&pruss_coreclk_mux>;
     assigned-clocks = <&pruss_iepclk_mux>;
     assigned-clock-parents = <&pruss_coreclk_mux>;
    };
   };
  };
  pruss_intc: interrupt-controller@20000 {
   compatible = "ti,pruss-intc";
   reg = <0x20000 0x2000>;
   interrupt-controller;
   #interrupt-cells = <3>;
   interrupts = <0 88 4>,
         <0 89 4>,
         <0 90 4>,
         <0 91 4>,
         <0 92 4>,
         <0 93 4>,
         <0 94 4>,
         <0 95 4>;
   interrupt-names = "host_intr0", "host_intr1",
       "host_intr2", "host_intr3",
       "host_intr4", "host_intr5",
       "host_intr6", "host_intr7";
  };
  pruss_uart: serial@28000 {
   compatible = "ti,pruss-uart";
   reg = <0x28000 0x40>;
   clocks = <&k3_clks 81 13>;
   interrupt-parent = <&pruss_intc>;
   interrupts = <6 4 4>;
   status = "disabled";
  };
  pru0: pru@34000 {
   compatible = "ti,am625-pru";
   reg = <0x34000 0x3000>,
         <0x22000 0x100>,
         <0x22400 0x100>;
   reg-names = "iram", "control", "debug";
   firmware-name = "am62x-pru0-fw";
   interrupt-parent = <&pruss_intc>;
   interrupts = <16 2 2>;
   interrupt-names = "vring";
  };
  pru1: pru@38000 {
   compatible = "ti,am625-pru";
   reg = <0x38000 0x3000>,
         <0x24000 0x100>,
         <0x24400 0x100>;
   reg-names = "iram", "control", "debug";
   firmware-name = "am62x-pru1-fw";
   interrupt-parent = <&pruss_intc>;
   interrupts = <18 3 3>;
   interrupt-names = "vring";
  };
 };
 gpmc0: memory-controller@3b000000 {
  compatible = "ti,am64-gpmc";
  power-domains = <&k3_pds 80 1>;
  clocks = <&k3_clks 80 0>;
  clock-names = "fck";
  reg = <0x00 0x03b000000 0x00 0x400>,
        <0x00 0x050000000 0x00 0x8000000>;
  reg-names = "cfg", "data";
  interrupts = <0 106 4>;
  gpmc,num-cs = <3>;
  gpmc,num-waitpins = <2>;
  #address-cells = <2>;
  #size-cells = <1>;
  interrupt-controller;
  #interrupt-cells = <2>;
  gpio-controller;
  #gpio-cells = <2>;
  status = "disabled";
 };
 elm0: ecc@25010000 {
  compatible = "ti,am64-elm";
  reg = <0x00 0x25010000 0x00 0x2000>;
  interrupts = <0 132 4>;
  power-domains = <&k3_pds 54 1>;
  clocks = <&k3_clks 54 0>;
  clock-names = "fck";
  status = "disabled";
 };
};
&cbass_mcu {
 mcu_pmx0: pinctrl@4084000 {
  bootph-all;
  compatible = "pinctrl-single";
  reg = <0x00 0x04084000 0x00 0x88>;
  #pinctrl-cells = <1>;
  pinctrl-single,register-width = <32>;
  pinctrl-single,function-mask = <0xffffffff>;
 };
 mcu_esm: esm@4100000 {
  bootph-pre-ram;
  compatible = "ti,j721e-esm";
  reg = <0x00 0x4100000 0x00 0x1000>;
  ti,esm-pins = <0>, <1>, <2>, <85>;
 };
 mcu_timer0: timer@4800000 {
  compatible = "ti,am654-timer";
  reg = <0x00 0x4800000 0x00 0x400>;
  clocks = <&k3_clks 35 2>;
  clock-names = "fck";
  power-domains = <&k3_pds 35 1>;
  ti,timer-pwm;
  status = "reserved";
 };
 mcu_timer1: timer@4810000 {
  compatible = "ti,am654-timer";
  reg = <0x00 0x4810000 0x00 0x400>;
  clocks = <&k3_clks 48 2>;
  clock-names = "fck";
  power-domains = <&k3_pds 48 1>;
  ti,timer-pwm;
  status = "reserved";
 };
 mcu_timer2: timer@4820000 {
  compatible = "ti,am654-timer";
  reg = <0x00 0x4820000 0x00 0x400>;
  clocks = <&k3_clks 49 2>;
  clock-names = "fck";
  power-domains = <&k3_pds 49 1>;
  ti,timer-pwm;
  status = "reserved";
 };
 mcu_timer3: timer@4830000 {
  compatible = "ti,am654-timer";
  reg = <0x00 0x4830000 0x00 0x400>;
  clocks = <&k3_clks 50 2>;
  clock-names = "fck";
  power-domains = <&k3_pds 50 1>;
  ti,timer-pwm;
  status = "reserved";
 };
 mcu_uart0: serial@4a00000 {
  compatible = "ti,am64-uart", "ti,am654-uart";
  reg = <0x00 0x04a00000 0x00 0x100>;
  interrupts = <0 185 4>;
  power-domains = <&k3_pds 149 1>;
  clocks = <&k3_clks 149 0>;
  clock-names = "fclk";
  status = "disabled";
 };
 mcu_i2c0: i2c@4900000 {
  compatible = "ti,am64-i2c", "ti,omap4-i2c";
  reg = <0x00 0x04900000 0x00 0x100>;
  interrupts = <0 107 4>;
  #address-cells = <1>;
  #size-cells = <0>;
  power-domains = <&k3_pds 106 1>;
  clocks = <&k3_clks 106 2>;
  clock-names = "fck";
  status = "disabled";
 };
 mcu_spi0: spi@4b00000 {
  compatible = "ti,am654-mcspi", "ti,omap4-mcspi";
  reg = <0x00 0x04b00000 0x00 0x400>;
  interrupts = <0 176 4>;
  #address-cells = <1>;
  #size-cells = <0>;
  power-domains = <&k3_pds 147 1>;
  clocks = <&k3_clks 147 0>;
  status = "disabled";
 };
 mcu_spi1: spi@4b10000 {
  compatible = "ti,am654-mcspi","ti,omap4-mcspi";
  reg = <0x00 0x04b10000 0x00 0x400>;
  interrupts = <0 177 4>;
  #address-cells = <1>;
  #size-cells = <0>;
  power-domains = <&k3_pds 148 1>;
  clocks = <&k3_clks 148 0>;
  status = "disabled";
 };
 mcu_gpio_intr: interrupt-controller@4210000 {
  compatible = "ti,sci-intr";
  reg = <0x00 0x04210000 0x00 0x200>;
  ti,intr-trigger-type = <1>;
  interrupt-controller;
  interrupt-parent = <&gic500>;
  #interrupt-cells = <1>;
  ti,sci = <&dmsc>;
  ti,sci-dev-id = <5>;
  ti,interrupt-ranges = <0 104 4>;
 };
 mcu_gpio0: gpio@4201000 {
  compatible = "ti,am64-gpio", "ti,keystone-gpio";
  reg = <0x00 0x4201000 0x00 0x100>;
  gpio-controller;
  #gpio-cells = <2>;
  interrupt-parent = <&mcu_gpio_intr>;
  interrupts = <30>, <31>;
  interrupt-controller;
  #interrupt-cells = <2>;
  ti,ngpio = <24>;
  ti,davinci-gpio-unbanked = <0>;
  power-domains = <&k3_pds 79 1>;
  clocks = <&k3_clks 79 0>;
  clock-names = "gpio";
 };
 mcu_rti0: watchdog@4880000 {
  compatible = "ti,j7-rti-wdt";
  reg = <0x00 0x04880000 0x00 0x100>;
  clocks = <&k3_clks 131 0>;
  power-domains = <&k3_pds 131 1>;
  assigned-clocks = <&k3_clks 131 0>;
  assigned-clock-parents = <&k3_clks 131 2>;
  status = "reserved";
 };
 mcu_mcan0: can@4e08000 {
  compatible = "bosch,m_can";
  reg = <0x00 0x4e08000 0x00 0x200>,
        <0x00 0x4e00000 0x00 0x8000>;
  reg-names = "m_can", "message_ram";
  power-domains = <&k3_pds 188 1>;
  clocks = <&k3_clks 188 6>, <&k3_clks 188 1>;
  clock-names = "hclk", "cclk";
  bosch,mram-cfg = <0x0 128 64 64 64 64 32 32>;
  status = "disabled";
 };
 mcu_mcan1: can@4e18000 {
  compatible = "bosch,m_can";
  reg = <0x00 0x4e18000 0x00 0x200>,
        <0x00 0x4e10000 0x00 0x8000>;
  reg-names = "m_can", "message_ram";
  power-domains = <&k3_pds 189 1>;
  clocks = <&k3_clks 189 6>, <&k3_clks 189 1>;
  clock-names = "hclk", "cclk";
  bosch,mram-cfg = <0x0 128 64 64 64 64 32 32>;
  status = "disabled";
 };
 mcu_m4fss: m4fss@5000000 {
  compatible = "ti,am64-m4fss";
  reg = <0x00 0x5000000 0x00 0x30000>,
        <0x00 0x5040000 0x00 0x10000>;
  reg-names = "iram", "dram";
  resets = <&k3_reset 9 1>;
  firmware-name = "am62-mcu-m4f0_0-fw";
  ti,sci = <&dmsc>;
  ti,sci-dev-id = <9>;
  ti,sci-proc-ids = <0x18 0xff>;
  status = "disabled";
 };
};
&cbass_wakeup {
 wkup_conf: bus@43000000 {
  bootph-all;
  compatible = "simple-bus";
  reg = <0x00 0x43000000 0x00 0x20000>;
  #address-cells = <1>;
  #size-cells = <1>;
  ranges = <0x0 0x00 0x43000000 0x20000>;
  chipid: chipid@14 {
   bootph-all;
   compatible = "ti,am654-chipid";
   reg = <0x14 0x4>;
  };
  opp_efuse_table: syscon@18 {
   compatible = "ti,am62-opp-efuse-table", "syscon";
   reg = <0x18 0x4>;
  };
  cpsw_mac_syscon: ethernet-mac-syscon@200 {
   compatible = "ti,am62p-cpsw-mac-efuse", "syscon";
   reg = <0x200 0x8>;
  };
  usb0_phy_ctrl: syscon@4008 {
   compatible = "ti,am62-usb-phy-ctrl", "syscon";
   reg = <0x4008 0x4>;
  };
  usb1_phy_ctrl: syscon@4018 {
   compatible = "ti,am62-usb-phy-ctrl", "syscon";
   reg = <0x4018 0x4>;
  };
 };
 target-module@2b300050 {
  compatible = "ti,sysc-omap2", "ti,sysc";
  reg = <0x00 0x2b300050 0x00 0x4>,
        <0x00 0x2b300054 0x00 0x4>,
        <0x00 0x2b300058 0x00 0x4>;
  reg-names = "rev", "sysc", "syss";
  ti,sysc-mask = <((1 << 2) |
     (1 << 1) |
     (1 << 0))>;
  ti,sysc-sidle = <0>,
    <1>,
    <2>,
    <3>;
  ti,syss-mask = <1>;
  ti,no-reset-on-init;
  power-domains = <&k3_pds 114 1>;
  clocks = <&k3_clks 114 0>;
  clock-names = "fck";
  #address-cells = <1>;
  #size-cells = <1>;
  ranges = <0x0 0x00 0x2b300000 0x100000>;
  wkup_uart0: serial@0 {
   compatible = "ti,am64-uart", "ti,am654-uart";
   reg = <0x0 0x100>;
   interrupts = <0 186 4>;
   status = "disabled";
  };
 };
 wkup_i2c0: i2c@2b200000 {
  compatible = "ti,am64-i2c", "ti,omap4-i2c";
  reg = <0x00 0x2b200000 0x00 0x100>;
  interrupts = <0 165 4>;
  #address-cells = <1>;
  #size-cells = <0>;
  power-domains = <&k3_pds 107 1>;
  clocks = <&k3_clks 107 4>;
  clock-names = "fck";
  status = "disabled";
 };
 wkup_rtc0: rtc@2b1f0000 {
  compatible = "ti,am62-rtc";
  reg = <0x00 0x2b1f0000 0x00 0x100>;
  interrupts = <0 100 4>;
  clocks = <&k3_clks 117 6> , <&k3_clks 117 0>;
  clock-names = "vbus", "osc32k";
  power-domains = <&k3_pds 117 1>;
  wakeup-source;
 };
 wkup_rti0: watchdog@2b000000 {
  compatible = "ti,j7-rti-wdt";
  reg = <0x00 0x2b000000 0x00 0x100>;
  clocks = <&k3_clks 132 0>;
  power-domains = <&k3_pds 132 1>;
  assigned-clocks = <&k3_clks 132 0>;
  assigned-clock-parents = <&k3_clks 132 2>;
  status = "reserved";
 };
 wkup_r5fss0: r5fss@78000000 {
  compatible = "ti,am62-r5fss";
  #address-cells = <1>;
  #size-cells = <1>;
  ranges = <0x78000000 0x00 0x78000000 0x8000>,
    <0x78100000 0x00 0x78100000 0x8000>;
  power-domains = <&k3_pds 119 1>;
  status = "disabled";
  wkup_r5fss0_core0: r5f@78000000 {
   compatible = "ti,am62-r5f";
   reg = <0x78000000 0x00008000>,
         <0x78100000 0x00008000>;
   reg-names = "atcm", "btcm";
   resets = <&k3_reset 121 1>;
   firmware-name = "am62-wkup-r5f0_0-fw";
   ti,atcm-enable = <1>;
   ti,btcm-enable = <1>;
   ti,loczrama = <1>;
   ti,sci = <&dmsc>;
   ti,sci-dev-id = <121>;
   ti,sci-proc-ids = <0x01 0xff>;
   status = "disabled";
  };
 };
 wkup_vtm0: temperature-sensor@b00000 {
  compatible = "ti,j7200-vtm";
  reg = <0x00 0xb00000 0x00 0x400>,
        <0x00 0xb01000 0x00 0x400>;
  power-domains = <&k3_pds 95 1>;
  #thermal-sensor-cells = <1>;
 };
};
/ {
 cpus {
  #address-cells = <1>;
  #size-cells = <0>;
  cpu-map {
   cluster0: cluster0 {
    core0 {
     cpu = <&cpu0>;
    };
    core1 {
     cpu = <&cpu1>;
    };
    core2 {
     cpu = <&cpu2>;
    };
    core3 {
     cpu = <&cpu3>;
    };
   };
  };
  cpu0: cpu@0 {
   compatible = "arm,cortex-a53";
   reg = <0x000>;
   device_type = "cpu";
   enable-method = "psci";
   i-cache-size = <0x8000>;
   i-cache-line-size = <64>;
   i-cache-sets = <256>;
   d-cache-size = <0x8000>;
   d-cache-line-size = <64>;
   d-cache-sets = <128>;
   next-level-cache = <&L2_0>;
   operating-points-v2 = <&a53_opp_table>;
   clocks = <&k3_clks 135 0>;
   #cooling-cells = <2>;
  };
  cpu1: cpu@1 {
   compatible = "arm,cortex-a53";
   reg = <0x001>;
   device_type = "cpu";
   enable-method = "psci";
   i-cache-size = <0x8000>;
   i-cache-line-size = <64>;
   i-cache-sets = <256>;
   d-cache-size = <0x8000>;
   d-cache-line-size = <64>;
   d-cache-sets = <128>;
   next-level-cache = <&L2_0>;
   operating-points-v2 = <&a53_opp_table>;
   clocks = <&k3_clks 136 0>;
   #cooling-cells = <2>;
  };
  cpu2: cpu@2 {
   compatible = "arm,cortex-a53";
   reg = <0x002>;
   device_type = "cpu";
   enable-method = "psci";
   i-cache-size = <0x8000>;
   i-cache-line-size = <64>;
   i-cache-sets = <256>;
   d-cache-size = <0x8000>;
   d-cache-line-size = <64>;
   d-cache-sets = <128>;
   next-level-cache = <&L2_0>;
   operating-points-v2 = <&a53_opp_table>;
   clocks = <&k3_clks 137 0>;
   #cooling-cells = <2>;
  };
  cpu3: cpu@3 {
   compatible = "arm,cortex-a53";
   reg = <0x003>;
   device_type = "cpu";
   enable-method = "psci";
   i-cache-size = <0x8000>;
   i-cache-line-size = <64>;
   i-cache-sets = <256>;
   d-cache-size = <0x8000>;
   d-cache-line-size = <64>;
   d-cache-sets = <128>;
   next-level-cache = <&L2_0>;
   operating-points-v2 = <&a53_opp_table>;
   clocks = <&k3_clks 138 0>;
   #cooling-cells = <2>;
  };
 };
 a53_opp_table: opp-table {
  compatible = "operating-points-v2-ti-cpu";
  opp-shared;
  syscon = <&opp_efuse_table>;
  ti,soc-info = <&chipid>;
  opp-200000000 {
   opp-hz = /bits/ 64 <200000000>;
   opp-supported-hw = <0x01 0x0007>;
   clock-latency-ns = <6000000>;
  };
  opp-400000000 {
   opp-hz = /bits/ 64 <400000000>;
   opp-supported-hw = <0x01 0x0007>;
   clock-latency-ns = <6000000>;
  };
  opp-600000000 {
   opp-hz = /bits/ 64 <600000000>;
   opp-supported-hw = <0x01 0x0007>;
   clock-latency-ns = <6000000>;
  };
  opp-800000000 {
   opp-hz = /bits/ 64 <800000000>;
   opp-supported-hw = <0x01 0x0007>;
   clock-latency-ns = <6000000>;
  };
  opp-1000000000 {
   opp-hz = /bits/ 64 <1000000000>;
   opp-supported-hw = <0x01 0x0006>;
   clock-latency-ns = <6000000>;
  };
  opp-1250000000 {
   opp-hz = /bits/ 64 <1250000000>;
   opp-supported-hw = <0x01 0x0004>;
   clock-latency-ns = <6000000>;
   opp-suspend;
  };
 };
 L2_0: l2-cache0 {
  compatible = "cache";
  cache-unified;
  cache-level = <2>;
  cache-size = <0x80000>;
  cache-line-size = <64>;
  cache-sets = <512>;
 };
};
/ {
 aliases {
  serial0 = &wkup_uart0;
  serial1 = &mcu_uart0;
  serial2 = &main_uart0;
  serial3 = &main_uart1;
  serial4 = &pruss_uart;
  mmc0 = &sdhci0;
  mmc1 = &sdhci1;
  mmc2 = &sdhci2;
  spi0 = &ospi0;
  ethernet0 = &cpsw_port1;
  ethernet1 = &cpsw_port2;
  usb0 = &usb0;
  usb1 = &usb1;
 };
 chosen {
  #address-cells = <2>;
  #size-cells = <2>;
  ranges;
  stdout-path = "serial2:115200n8";
  framebuffer0: framebuffer@0 {
   compatible = "simple-framebuffer";
   power-domains = <&k3_pds 186 1>;
   clocks = <&k3_clks 186 6>,
     <&dss_vp1_clk>,
     <&k3_clks 186 2>;
   display = <&dss>;
   status = "disabled";
  };
 };
 reserved_memory: reserved-memory {
  #address-cells = <2>;
  #size-cells = <2>;
  ranges;
  ramoops@9c700000 {
   compatible = "ramoops";
   reg = <0x00 0x9c700000 0x00 0x00100000>;
   record-size = <0x8000>;
   console-size = <0x8000>;
   ftrace-size = <0x00>;
   pmsg-size = <0x8000>;
  };
  1,cma {
   compatible = "shared-dma-pool";
   reusable;
   size = <0x00 0x8000000>;
   1,cma-default;
  };
  wkup_r5fss0_core0_dma_memory_region: memory@9da00000 {
   compatible = "shared-dma-pool";
   reg = <0x00 0x9da00000 0x00 0x100000>;
   no-map;
  };
  wkup_r5fss0_core0_memory_region: memory@9db00000 {
   compatible = "shared-dma-pool";
   reg = <0x00 0x9db00000 0x00 0xc00000>;
   no-map;
  };
  secure_tfa_ddr: tfa@9e780000 {
   reg = <0x00 0x9e780000 0x00 0x80000>;
   alignment = <0x1000>;
   no-map;
  };
  secure_ddr: optee@9e800000 {
   reg = <0x00 0x9e800000 0x00 0x01800000>;
   alignment = <0x1000>;
   no-map;
  };
 };
 leds {
  compatible = "gpio-leds";
  pinctrl-names = "default";
  pinctrl-0 = <&usr_led_pins_default>;
  led-0 {
   label = "am62-sk:green:heartbeat";
   gpios = <&main_gpio1 49 0>;
   1,default-trigger = "heartbeat";
   function = "heartbeat";
   default-state = "off";
  };
 };
 tlv320_mclk: clk-0 {
  #clock-cells = <0>;
  compatible = "fixed-clock";
  clock-frequency = <12288000>;
 };
 codec_audio: sound {
  compatible = "simple-audio-card";
  simple-audio-card,name = "AM62x-SKEVM";
  simple-audio-card,widgets =
   "Headphone", "Headphone Jack",
   "Line", "Line In",
   "Microphone", "Microphone Jack";
  simple-audio-card,routing =
   "Headphone Jack", "HPLOUT",
   "Headphone Jack", "HPROUT",
   "LINE1L", "Line In",
   "LINE1R", "Line In",
   "MIC3R", "Microphone Jack",
   "Microphone Jack", "Mic Bias";
  simple-audio-card,format = "dsp_b";
  simple-audio-card,bitclock-master = <&sound_master>;
  simple-audio-card,frame-master = <&sound_master>;
  simple-audio-card,bitclock-inversion;
  simple-audio-card,cpu {
   sound-dai = <&mcasp1>;
  };
  sound_master: simple-audio-card,codec {
   sound-dai = <&tlv320aic3106>;
   clocks = <&tlv320_mclk>;
  };
 };
 hdmi0: connector-hdmi {
  compatible = "hdmi-connector";
  label = "hdmi";
  type = "a";
  port {
   hdmi_connector_in: endpoint {
    remote-endpoint = <&sii9022_out>;
   };
  };
 };
};
&phy_gmii_sel {
 bootph-all;
};
&main_pmx0 {
 main_uart0_pins_default: main-uart0-default-pins {
  bootph-all;
  pinctrl-single,pins = <
   (((0x1c8) & 0x1fff)) ((((1 << (18)) | (1 << (14)) | (1 << (16)))) | (0))
   (((0x1cc) & 0x1fff)) ((((0 << (18)) | (1 << (16)))) | (0))
  >;
 };
 main_uart0_pins_wakeup: main-uart0-wakeup-pins {
  pinctrl-single,pins = <
   (((0x1c8) & 0x1fff)) ((((1 << (18)) | (1 << (14)) | (1 << (16))) | ((1 << (29)) | (0 << (7)))) | (0))
   (((0x1cc) & 0x1fff)) ((((0 << (18)) | (1 << (16)))) | (0))
  >;
 };
 main_uart1_pins_default: main-uart1-default-pins {
  bootph-pre-ram;
  pinctrl-single,pins = <
   (((0x194) & 0x1fff)) ((((1 << (18)) | (1 << (14)) | (1 << (16)))) | (2))
   (((0x198) & 0x1fff)) ((((0 << (18)) | (1 << (16)))) | (2))
   (((0x1ac) & 0x1fff)) ((((1 << (18)) | (1 << (14)) | (1 << (16)))) | (2))
   (((0x1b0) & 0x1fff)) ((((0 << (18)) | (1 << (16)))) | (2))
  >;
 };
 main_i2c0_pins_default: main-i2c0-default-pins {
  pinctrl-single,pins = <
   (((0x1e0) & 0x1fff)) ((((1 << (18)) | (1 << (14)) | (1 << (17) | (0 << (16))))) | (0))
   (((0x1e4) & 0x1fff)) ((((1 << (18)) | (1 << (14)) | (1 << (17) | (0 << (16))))) | (0))
  >;
 };
 main_i2c1_pins_default: main-i2c1-default-pins {
  bootph-all;
  pinctrl-single,pins = <
   (((0x1e8) & 0x1fff)) ((((1 << (18)) | (1 << (14)) | (1 << (17) | (0 << (16))))) | (0))
   (((0x1ec) & 0x1fff)) ((((1 << (18)) | (1 << (14)) | (1 << (17) | (0 << (16))))) | (0))
  >;
 };
 main_i2c2_pins_default: main-i2c2-default-pins {
  pinctrl-single,pins = <
   (((0x0b0) & 0x1fff)) ((((1 << (18)) | (1 << (14)) | (1 << (17) | (0 << (16))))) | (1))
   (((0x0b4) & 0x1fff)) ((((1 << (18)) | (1 << (14)) | (1 << (17) | (0 << (16))))) | (1))
  >;
 };
 main_mmc1_pins_default: main-mmc1-default-pins {
  bootph-all;
  pinctrl-single,pins = <
   (((0x23c) & 0x1fff)) ((((1 << (18)) | (1 << (14)) | (1 << (16)))) | (0))
   (((0x234) & 0x1fff)) ((((1 << (18)) | (1 << (14)) | (1 << (16)))) | (0))
   (((0x230) & 0x1fff)) ((((1 << (18)) | (1 << (14)) | (1 << (16)))) | (0))
   (((0x22c) & 0x1fff)) ((((1 << (18)) | (1 << (14)) | (1 << (16)))) | (0))
   (((0x228) & 0x1fff)) ((((1 << (18)) | (1 << (14)) | (1 << (16)))) | (0))
   (((0x224) & 0x1fff)) ((((1 << (18)) | (1 << (14)) | (1 << (16)))) | (0))
   (((0x240) & 0x1fff)) ((((1 << (18)) | (1 << (14)) | (1 << (16)))) | (0))
  >;
 };
 usr_led_pins_default: usr-led-default-pins {
  pinctrl-single,pins = <
   (((0x244) & 0x1fff)) ((((0 << (18)) | (1 << (16)))) | (7))
  >;
 };
 main_mdio1_pins_default: main-mdio1-default-pins {
  pinctrl-single,pins = <
   (((0x160) & 0x1fff)) ((((0 << (18)) | (1 << (16)))) | (0))
   (((0x15c) & 0x1fff)) ((((1 << (18)) | (1 << (14)) | (1 << (16)))) | (0))
  >;
 };
 main_rgmii1_pins_default: main-rgmii1-default-pins {
  bootph-all;
  pinctrl-single,pins = <
   (((0x14c) & 0x1fff)) ((((1 << (18)) | (1 << (14)) | (1 << (16)))) | (0))
   (((0x150) & 0x1fff)) ((((1 << (18)) | (1 << (14)) | (1 << (16)))) | (0))
   (((0x154) & 0x1fff)) ((((1 << (18)) | (1 << (14)) | (1 << (16)))) | (0))
   (((0x158) & 0x1fff)) ((((1 << (18)) | (1 << (14)) | (1 << (16)))) | (0))
   (((0x148) & 0x1fff)) ((((1 << (18)) | (1 << (14)) | (1 << (16)))) | (0))
   (((0x144) & 0x1fff)) ((((1 << (18)) | (1 << (14)) | (1 << (16)))) | (0))
   (((0x134) & 0x1fff)) ((((0 << (18)) | (1 << (16)))) | (0))
   (((0x138) & 0x1fff)) ((((0 << (18)) | (1 << (16)))) | (0))
   (((0x13c) & 0x1fff)) ((((0 << (18)) | (1 << (16)))) | (0))
   (((0x140) & 0x1fff)) ((((0 << (18)) | (1 << (16)))) | (0))
   (((0x130) & 0x1fff)) ((((0 << (18)) | (1 << (16)))) | (0))
   (((0x12c) & 0x1fff)) ((((0 << (18)) | (1 << (16)))) | (0))
  >;
 };
 main_usb1_pins_default: main-usb1-default-pins {
  pinctrl-single,pins = <
   (((0x0258) & 0x1fff)) ((((0 << (18)) | (1 << (16)))) | (0))
  >;
 };
 main_mcasp1_pins_default: main-mcasp1-default-pins {
  pinctrl-single,pins = <
   (((0x090) & 0x1fff)) ((((1 << (18)) | (1 << (14)) | (1 << (16)))) | (2))
   (((0x098) & 0x1fff)) ((((1 << (18)) | (1 << (14)) | (1 << (16)))) | (2))
   (((0x08c) & 0x1fff)) ((((0 << (18)) | (1 << (16)))) | (2))
   (((0x084) & 0x1fff)) ((((1 << (18)) | (1 << (14)) | (1 << (16)))) | (2))
  >;
 };
 main_dss0_pins_default: main-dss0-default-pins {
  pinctrl-single,pins = <
   (((0x100) & 0x1fff)) ((((0 << (18)) | (1 << (16)))) | (0))
   (((0x0f8) & 0x1fff)) ((((0 << (18)) | (1 << (16)))) | (0))
   (((0x104) & 0x1fff)) ((((0 << (18)) | (1 << (16)))) | (0))
   (((0x0fc) & 0x1fff)) ((((0 << (18)) | (1 << (16)))) | (0))
   (((0x0b8) & 0x1fff)) ((((0 << (18)) | (1 << (16)))) | (0))
   (((0x0bc) & 0x1fff)) ((((0 << (18)) | (1 << (16)))) | (0))
   (((0x0c0) & 0x1fff)) ((((0 << (18)) | (1 << (16)))) | (0))
   (((0x0c4) & 0x1fff)) ((((0 << (18)) | (1 << (16)))) | (0))
   (((0x0c8) & 0x1fff)) ((((0 << (18)) | (1 << (16)))) | (0))
   (((0x0cc) & 0x1fff)) ((((0 << (18)) | (1 << (16)))) | (0))
   (((0x0d0) & 0x1fff)) ((((0 << (18)) | (1 << (16)))) | (0))
   (((0x0d4) & 0x1fff)) ((((0 << (18)) | (1 << (16)))) | (0))
   (((0x0d8) & 0x1fff)) ((((0 << (18)) | (1 << (16)))) | (0))
   (((0x0dc) & 0x1fff)) ((((0 << (18)) | (1 << (16)))) | (0))
   (((0x0e0) & 0x1fff)) ((((0 << (18)) | (1 << (16)))) | (0))
   (((0x0e4) & 0x1fff)) ((((0 << (18)) | (1 << (16)))) | (0))
   (((0x0e8) & 0x1fff)) ((((0 << (18)) | (1 << (16)))) | (0))
   (((0x0ec) & 0x1fff)) ((((0 << (18)) | (1 << (16)))) | (0))
   (((0x0f0) & 0x1fff)) ((((0 << (18)) | (1 << (16)))) | (0))
   (((0x0f4) & 0x1fff)) ((((0 << (18)) | (1 << (16)))) | (0))
   (((0x05c) & 0x1fff)) ((((0 << (18)) | (1 << (16)))) | (1))
   (((0x060) & 0x1fff)) ((((0 << (18)) | (1 << (16)))) | (1))
   (((0x064) & 0x1fff)) ((((0 << (18)) | (1 << (16)))) | (1))
   (((0x068) & 0x1fff)) ((((0 << (18)) | (1 << (16)))) | (1))
   (((0x06c) & 0x1fff)) ((((0 << (18)) | (1 << (16)))) | (1))
   (((0x070) & 0x1fff)) ((((0 << (18)) | (1 << (16)))) | (1))
   (((0x074) & 0x1fff)) ((((0 << (18)) | (1 << (16)))) | (1))
   (((0x078) & 0x1fff)) ((((0 << (18)) | (1 << (16)))) | (1))
  >;
 };
 ospi0_pins_default: ospi0-default-pins {
  bootph-all;
  pinctrl-single,pins = <
   (((0x000) & 0x1fff)) ((((0 << (18)) | (1 << (16)))) | (0))
   (((0x02c) & 0x1fff)) ((((0 << (18)) | (1 << (16)))) | (0))
   (((0x00c) & 0x1fff)) ((((1 << (18)) | (1 << (14)) | (1 << (16)))) | (0))
   (((0x010) & 0x1fff)) ((((1 << (18)) | (1 << (14)) | (1 << (16)))) | (0))
   (((0x014) & 0x1fff)) ((((1 << (18)) | (1 << (14)) | (1 << (16)))) | (0))
   (((0x018) & 0x1fff)) ((((1 << (18)) | (1 << (14)) | (1 << (16)))) | (0))
   (((0x01c) & 0x1fff)) ((((1 << (18)) | (1 << (14)) | (1 << (16)))) | (0))
   (((0x020) & 0x1fff)) ((((1 << (18)) | (1 << (14)) | (1 << (16)))) | (0))
   (((0x024) & 0x1fff)) ((((1 << (18)) | (1 << (14)) | (1 << (16)))) | (0))
   (((0x028) & 0x1fff)) ((((1 << (18)) | (1 << (14)) | (1 << (16)))) | (0))
   (((0x008) & 0x1fff)) ((((1 << (18)) | (1 << (14)) | (1 << (16)))) | (0))
  >;
 };
 main_ecap0_pins_default: main-ecap0-default-pins {
  pinctrl-single,pins = <
   (((0x01b8) & 0x1fff)) ((((0 << (18)) | (1 << (16)))) | (3))
  >;
 };
 main_ecap2_pins_default: main-ecap2-default-pins {
  pinctrl-single,pins = <
   (((0x01a4) & 0x1fff)) ((((0 << (18)) | (1 << (16)))) | (2))
  >;
 };
 main_epwm1_pins_default: main-epwm1-default-pins {
  pinctrl-single,pins = <
   (((0x019c) & 0x1fff)) ((((0 << (18)) | (1 << (16)))) | (6))
   (((0x01a0) & 0x1fff)) ((((0 << (18)) | (1 << (16)))) | (6))
  >;
 };
 pruss_uart_pins: pruss-uart-pins {
  pinctrl-single,pins = <
   (((0x01d8) & 0x1fff)) ((((1 << (18)) | (1 << (14)) | (1 << (16)))) | (6))
   (((0x01dc) & 0x1fff)) ((((0 << (18)) | (1 << (16)))) | (6))
  >;
 };
};
&mcu_pmx0 {
 wkup_uart0_pins_default: wkup-uart0-default-pins {
  bootph-pre-ram;
  pinctrl-single,pins = <
   (((0x02c) & 0x1fff)) ((((1 << (18)) | (1 << (14)) | (1 << (16)))) | (0))
   (((0x030) & 0x1fff)) ((((0 << (18)) | (1 << (16)))) | (0))
   (((0x024) & 0x1fff)) ((((1 << (18)) | (1 << (14)) | (1 << (16)))) | (0))
   (((0x028) & 0x1fff)) ((((0 << (18)) | (1 << (16)))) | (0))
  >;
 };
};
&cpsw_mac_syscon {
 bootph-all;
};
&wkup_uart0 {
 bootph-pre-ram;
 status = "reserved";
 pinctrl-names = "default";
 pinctrl-0 = <&wkup_uart0_pins_default>;
};
&main_uart0 {
 bootph-all;
 status = "okay";
 pinctrl-names = "default", "wakeup";
 pinctrl-0 = <&main_uart0_pins_default>;
 pinctrl-1 = <&main_uart0_pins_wakeup>;
 wakeup-source = <&system_deep_sleep>,
   <&system_mcu_only>,
   <&system_standby>;
};
&main_uart1 {
 bootph-pre-ram;
 status = "reserved";
 pinctrl-names = "default";
 pinctrl-0 = <&main_uart1_pins_default>;
};
&main_i2c0 {
 status = "okay";
 pinctrl-names = "default";
 pinctrl-0 = <&main_i2c0_pins_default>;
 clock-frequency = <400000>;
 eeprom@51 {
  compatible = "atmel,24c512";
  reg = <0x51>;
 };
 typec_pd0: tps6598x@3f {
  compatible = "ti,tps6598x";
  reg = <0x3f>;
  connector {
   compatible = "usb-c-connector";
   label = "USB-C";
   self-powered;
   data-role = "dual";
   power-role = "sink";
   port {
    usb_con_hs: endpoint {
     remote-endpoint = <&usb0_hs_ep>;
    };
   };
  };
 };
};
&main_i2c1 {
 status = "okay";
 pinctrl-names = "default";
 pinctrl-0 = <&main_i2c1_pins_default>;
 clock-frequency = <100000>;
 tlv320aic3106: audio-codec@1b {
  #sound-dai-cells = <0>;
  compatible = "ti,tlv320aic3106";
  reg = <0x1b>;
  ai3x-micbias-vg = <1>;
  AVDD-supply = <&vcc_3v3_sys>;
  IOVDD-supply = <&vcc_3v3_sys>;
  DRVDD-supply = <&vcc_3v3_sys>;
 };
 sii9022: bridge-hdmi@3b {
  compatible = "sil,sii9022";
  reg = <0x3b>;
  interrupt-parent = <&exp1>;
  interrupts = <16 2>;
  #sound-dai-cells = <0>;
  sil,i2s-data-lanes = < 0 >;
  ports {
   #address-cells = <1>;
   #size-cells = <0>;
   port@0 {
    reg = <0>;
    sii9022_in: endpoint {
     remote-endpoint = <&dpi1_out>;
    };
   };
   port@1 {
    reg = <1>;
    sii9022_out: endpoint {
     remote-endpoint = <&hdmi_connector_in>;
    };
   };
  };
 };
};
&main_i2c2 {
 status = "okay";
 pinctrl-names = "default";
 pinctrl-0 = <&main_i2c2_pins_default>;
 clock-frequency = <400000>;
};
&sdhci1 {
 bootph-all;
 status = "okay";
 pinctrl-names = "default";
 pinctrl-0 = <&main_mmc1_pins_default>;
 disable-wp;
};
&cpsw3g {
 bootph-all;
 pinctrl-names = "default";
 pinctrl-0 = <&main_rgmii1_pins_default>;
 cpts@3d000 {
  ti,pps = <2 1>;
 };
};
&cpsw_port1 {
 bootph-all;
 phy-mode = "rgmii-rxid";
 phy-handle = <&cpsw3g_phy0>;
};
&cpsw3g_mdio {
 bootph-all;
 status = "okay";
 pinctrl-names = "default";
 pinctrl-0 = <&main_mdio1_pins_default>;
 cpsw3g_phy0: ethernet-phy@0 {
  bootph-all;
  reg = <0>;
  ti,rx-internal-delay = <0x7>;
  ti,fifo-depth = <0x01>;
  ti,min-output-impedance;
 };
};
&usbss0 {
 bootph-all;
 status = "okay";
 ti,vbus-divider;
};
&usbss1 {
 status = "okay";
 ti,vbus-divider;
};
&usb0 {
 bootph-all;
 usb-role-switch;
 port {
  usb0_hs_ep: endpoint {
      remote-endpoint = <&usb_con_hs>;
        };
 };
};
&usb0_phy_ctrl {
 bootph-all;
};
&usb1 {
 dr_mode = "host";
 pinctrl-names = "default";
 pinctrl-0 = <&main_usb1_pins_default>;
};
&mcasp1 {
 status = "okay";
 #sound-dai-cells = <0>;
 pinctrl-names = "default";
 pinctrl-0 = <&main_mcasp1_pins_default>;
 op-mode = <0>;
 tdm-slots = <2>;
 serial-dir = <
        1 0 2 0
        0 0 0 0
        0 0 0 0
        0 0 0 0
 >;
};
&dss_oldi_io_ctrl {
 bootph-all;
};
&dss {
 bootph-all;
 status = "okay";
 pinctrl-names = "default";
 pinctrl-0 = <&main_dss0_pins_default>;
};
&dss_ports {
 port@1 {
  reg = <1>;
  dpi1_out: endpoint {
   remote-endpoint = <&sii9022_in>;
  };
 };
};
&mcu_gpio0 {
 status = "reserved";
};
&mcu_gpio_intr {
 status = "reserved";
};
&main_bcdma {
 bootph-all;
};
&main_pktdma {
 bootph-all;
};
&ospi0 {
 bootph-all;
 status = "okay";
 pinctrl-names = "default";
 pinctrl-0 = <&ospi0_pins_default>;
};
&ecap0 {
 pinctrl-names = "default";
 pinctrl-0 = <&main_ecap0_pins_default>;
 status = "okay";
};
&ecap2 {
 pinctrl-names = "default";
 pinctrl-0 = <&main_ecap2_pins_default>;
 status = "okay";
};
&epwm1 {
 pinctrl-names = "default";
 pinctrl-0 = <&main_epwm1_pins_default>;
 status = "okay";
};
&pruss_uart {
 pinctrl-names = "default";
 pinctrl-0 = <&pruss_uart_pins>;
 status = "okay";
};
&timesync_router {
 mux-reg-mask-val = <
  ((0x4 + ((12) * 4))) (0xff) (17)
  >;
 idle-states = <0x1>;
 status = "okay";
};
&reserved_memory {
 rtos_ipc_memory_region: ipc-memories@9c800000 {
  compatible = "shared-dma-pool";
  reg = <0x00 0x9c800000 0x00 0x00300000>;
  no-map;
 };
 mcu_m4fss_dma_memory_region: memory@9cb00000 {
  compatible = "shared-dma-pool";
  reg = <0x00 0x9cb00000 0x00 0x100000>;
  no-map;
 };
 mcu_m4fss_memory_region: memory@9cc00000 {
  compatible = "shared-dma-pool";
  reg = <0x00 0x9cc00000 0x00 0xe00000>;
  no-map;
 };
};
&mailbox0_cluster0 {
 status = "okay";
 mbox_m4_0: mbox-m4-0 {
  ti,mbox-rx = <0 0 0>;
  ti,mbox-tx = <1 0 0>;
 };
 mbox_r5_0: mbox-r5-0 {
  ti,mbox-rx = <2 0 0>;
  ti,mbox-tx = <3 0 0>;
 };
};
&mcu_m4fss {
 mboxes = <&mailbox0_cluster0 &mbox_m4_0>;
 memory-region = <&mcu_m4fss_dma_memory_region>,
   <&mcu_m4fss_memory_region>;
 status = "okay";
};
&wkup_r5fss0 {
 status = "okay";
};
&wkup_r5fss0_core0 {
 mboxes = <&mailbox0_cluster0 &mbox_r5_0>;
 memory-region = <&wkup_r5fss0_core0_dma_memory_region>,
   <&wkup_r5fss0_core0_memory_region>;
 status = "okay";
};
/ {
 opp-table {
  opp-1400000000 {
   opp-hz = /bits/ 64 <1400000000>;
   opp-supported-hw = <0x01 0x0004>;
   clock-latency-ns = <6000000>;
  };
 };
 vmain_pd: regulator-0 {
  compatible = "regulator-fixed";
  regulator-name = "vmain_pd";
  regulator-min-microvolt = <5000000>;
  regulator-max-microvolt = <5000000>;
  regulator-always-on;
  regulator-boot-on;
  bootph-all;
 };
 vcc_5v0: regulator-1 {
  compatible = "regulator-fixed";
  regulator-name = "vcc_5v0";
  regulator-min-microvolt = <5000000>;
  regulator-max-microvolt = <5000000>;
  vin-supply = <&vmain_pd>;
  regulator-always-on;
  regulator-boot-on;
  bootph-all;
 };
 vcc_3v3_sys: regulator-2 {
  compatible = "regulator-fixed";
  regulator-name = "vcc_3v3_sys";
  regulator-min-microvolt = <3300000>;
  regulator-max-microvolt = <3300000>;
  vin-supply = <&vmain_pd>;
  regulator-always-on;
  regulator-boot-on;
  bootph-all;
 };
 vdd_mmc1: regulator-3 {
  compatible = "regulator-fixed";
  regulator-name = "vdd_mmc1";
  regulator-min-microvolt = <3300000>;
  regulator-max-microvolt = <3300000>;
  regulator-boot-on;
  enable-active-high;
  vin-supply = <&vcc_3v3_sys>;
  gpio = <&exp1 3 0>;
  bootph-all;
 };
 vdd_sd_dv: regulator-4 {
  compatible = "regulator-gpio";
  regulator-name = "tlv71033";
  pinctrl-names = "default";
  pinctrl-0 = <&vdd_sd_dv_pins_default>;
  regulator-min-microvolt = <1800000>;
  regulator-max-microvolt = <3300000>;
  regulator-boot-on;
  vin-supply = <&vcc_5v0>;
  gpios = <&main_gpio0 31 0>;
  states = <1800000 0x0>,
    <3300000 0x1>;
  bootph-all;
 };
 vcc_1v8: regulator-5 {
  compatible = "regulator-fixed";
  regulator-name = "vcc_1v8";
  regulator-min-microvolt = <1800000>;
  regulator-max-microvolt = <1800000>;
  vin-supply = <&vcc_3v3_sys>;
  regulator-always-on;
  regulator-boot-on;
 };
};
&main_pmx0 {
 main_mmc0_pins_default: main-mmc0-default-pins {
  bootph-all;
  pinctrl-single,pins = <
   (((0x220) & 0x1fff)) ((((1 << (18)) | (1 << (14)) | (1 << (16)))) | (0))
   (((0x218) & 0x1fff)) ((((1 << (18)) | (1 << (14)) | (1 << (16)))) | (0))
   (((0x214) & 0x1fff)) ((((1 << (18)) | (1 << (14)) | (1 << (16)))) | (0))
   (((0x210) & 0x1fff)) ((((1 << (18)) | (1 << (14)) | (1 << (17) | (0 << (16))))) | (0))
   (((0x20c) & 0x1fff)) ((((1 << (18)) | (1 << (14)) | (1 << (17) | (0 << (16))))) | (0))
   (((0x208) & 0x1fff)) ((((1 << (18)) | (1 << (14)) | (1 << (17) | (0 << (16))))) | (0))
   (((0x204) & 0x1fff)) ((((1 << (18)) | (1 << (14)) | (1 << (17) | (0 << (16))))) | (0))
   (((0x200) & 0x1fff)) ((((1 << (18)) | (1 << (14)) | (1 << (17) | (0 << (16))))) | (0))
   (((0x1fc) & 0x1fff)) ((((1 << (18)) | (1 << (14)) | (1 << (17) | (0 << (16))))) | (0))
   (((0x1f8) & 0x1fff)) ((((1 << (18)) | (1 << (14)) | (1 << (17) | (0 << (16))))) | (0))
  >;
 };
 main_rgmii2_pins_default: main-rgmii2-default-pins {
  bootph-all;
  pinctrl-single,pins = <
   (((0x184) & 0x1fff)) ((((1 << (18)) | (1 << (14)) | (1 << (16)))) | (0))
   (((0x188) & 0x1fff)) ((((1 << (18)) | (1 << (14)) | (1 << (16)))) | (0))
   (((0x18c) & 0x1fff)) ((((1 << (18)) | (1 << (14)) | (1 << (16)))) | (0))
   (((0x190) & 0x1fff)) ((((1 << (18)) | (1 << (14)) | (1 << (16)))) | (0))
   (((0x180) & 0x1fff)) ((((1 << (18)) | (1 << (14)) | (1 << (16)))) | (0))
   (((0x17c) & 0x1fff)) ((((1 << (18)) | (1 << (14)) | (1 << (16)))) | (0))
   (((0x16c) & 0x1fff)) ((((0 << (18)) | (1 << (16)))) | (0))
   (((0x170) & 0x1fff)) ((((0 << (18)) | (1 << (16)))) | (0))
   (((0x174) & 0x1fff)) ((((0 << (18)) | (1 << (16)))) | (0))
   (((0x178) & 0x1fff)) ((((0 << (18)) | (1 << (16)))) | (0))
   (((0x168) & 0x1fff)) ((((0 << (18)) | (1 << (16)))) | (0))
   (((0x164) & 0x1fff)) ((((0 << (18)) | (1 << (16)))) | (0))
  >;
 };
 vdd_sd_dv_pins_default: vdd-sd-dv-default-pins {
  pinctrl-single,pins = <
   (((0x07c) & 0x1fff)) ((((0 << (18)) | (1 << (16)))) | (7))
  >;
  bootph-all;
 };
 main_gpio1_ioexp_intr_pins_default: main-gpio1-ioexp-intr-default-pins {
  pinctrl-single,pins = <
   (((0x01d4) & 0x1fff)) ((((1 << (18)) | (1 << (14)) | (1 << (16)))) | (7))
  >;
  bootph-all;
 };
};
&main_gpio0 {
 bootph-all;
};
&main_gpio1 {
 bootph-all;
};
&main_i2c1 {
 exp1: gpio@22 {
  compatible = "ti,tca6424";
  reg = <0x22>;
  pinctrl-names = "default";
  pinctrl-0 = <&main_gpio1_ioexp_intr_pins_default>;
  interrupt-parent = <&main_gpio1>;
  interrupts = <23 2>;
  interrupt-controller;
  #interrupt-cells = <2>;
  gpio-controller;
  #gpio-cells = <2>;
  gpio-line-names = "GPIO_CPSW2_RST", "GPIO_CPSW1_RST",
       "PRU_DETECT", "MMC1_SD_EN",
       "VPP_LDO_EN", "EXP_PS_3V3_En",
       "EXP_PS_5V0_En", "EXP_HAT_DETECT",
       "GPIO_AUD_RSTn", "GPIO_eMMC_RSTn",
       "UART1_FET_BUF_EN", "WL_LT_EN",
       "GPIO_HDMI_RSTn", "CSI_GPIO1",
       "CSI_GPIO2", "PRU_3V3_EN",
       "HDMI_INTn", "PD_I2C_IRQ",
       "MCASP1_FET_EN", "MCASP1_BUF_BT_EN",
       "MCASP1_FET_SEL", "UART1_FET_SEL",
       "TSINT#", "IO_EXP_TEST_LED";
  bootph-all;
 };
};
&sdhci0 {
 bootph-all;
 non-removable;
 status = "okay";
 pinctrl-names = "default";
 pinctrl-0 = <&main_mmc0_pins_default>;
 disable-wp;
};
&sdhci1 {
 vmmc-supply = <&vdd_mmc1>;
 vqmmc-supply = <&vdd_sd_dv>;
};
&cpsw3g {
 pinctrl-names = "default";
 pinctrl-0 = <&main_rgmii1_pins_default>, <&main_rgmii2_pins_default>;
};
&cpsw_port2 {
 phy-mode = "rgmii-rxid";
 phy-handle = <&cpsw3g_phy1>;
};
&cpsw3g_mdio {
 cpsw3g_phy1: ethernet-phy@1 {
  reg = <1>;
  ti,rx-internal-delay = <0x7>;
  ti,fifo-depth = <0x01>;
  ti,min-output-impedance;
 };
};
&fss {
 bootph-all;
};
&ospi0 {
 flash@0 {
  compatible = "jedec,spi-nor";
  reg = <0x0>;
  spi-tx-bus-width = <8>;
  spi-rx-bus-width = <8>;
  spi-max-frequency = <166000000>;
  cdns,tshsl-ns = <60>;
  cdns,tsd2d-ns = <60>;
  cdns,tchsh-ns = <60>;
  cdns,tslch-ns = <60>;
  cdns,read-delay = <4>;
  bootph-all;
  partitions {
   compatible = "fixed-partitions";
   #address-cells = <1>;
   #size-cells = <1>;
   bootph-all;
   partition@0 {
    label = "ospi.tiboot3";
    reg = <0x0 0x80000>;
   };
   partition@80000 {
    label = "ospi.tispl";
    reg = <0x80000 0x200000>;
   };
   partition@280000 {
    label = "ospi.u-boot";
    reg = <0x280000 0x400000>;
   };
   partition@680000 {
    label = "ospi.env";
    reg = <0x680000 0x40000>;
   };
   partition@6c0000 {
    label = "ospi.env.backup";
    reg = <0x6c0000 0x40000>;
   };
   partition@800000 {
    label = "ospi.rootfs";
    reg = <0x800000 0x37c0000>;
   };
   partition@3fc0000 {
    bootph-pre-ram;
    label = "ospi.phypattern";
    reg = <0x3fc0000 0x40000>;
   };
  };
 };
};
/ {
    compatible = "ti,am625-sk", "ti,am625";
    model = "Texas Instruments AM625 SK";
    memory@80000000 {
        reg = <0x00000000 0x80000000 0x00000000 0x80000000>;
        device_type = "memory";
        bootph-pre-ram;
    };
    ems_mmc_part {
        emspart = "ems-mmc";
        partitions {
            compatible = "fixed-partitions";
            #address-cells = <1>;
            #size-cells = <1>;
            partition@0 {label = "loader0"; reg = <0x00000000 0x00400000>; };
            partition@400000 {label = "loader1"; reg = <0x00400000 0x00400000>; };
            partition@800000 {label = "ubootenv"; reg = <0x00800000 0x00080000>; bootable; };
            partition@880000 {label = "sysflag"; reg = <0x00880000 0x00080000>; bootable; };
            partition@900000 {label = "fdt0"; reg = <0x00900000 0x00080000>; };
            partition@980000 {label = "fdt1"; reg = <0x00980000 0x00080000>; };
            partition@A00000 {label = "fdt2"; reg = <0x00A00000 0x00080000>; };
            partition@A80000 {label = "teeos0"; reg = <0x00A80000 0x00400000>; };
            partition@E80000 {label = "teeos1"; reg = <0x00E80000 0x00400000>; };
            partition@1280000 {label = "teeos2"; reg = <0x01280000 0x00400000>; };
            partition@1680000 {label = "uboot0"; reg = <0x01680000 0x00400000>; };
            partition@1A80000 {label = "uboot1"; reg = <0x01A80000 0x00400000>; };
            partition@1E80000 {label = "uboot2"; reg = <0x01E80000 0x00400000>; };
            partition@2280000 {label = "kernel0"; reg = <0x02280000 0x02000000>; };
            partition@4280000 {label = "kernel1"; reg = <0x04280000 0x02000000>; };
            partition@6280000 {label = "kernel2"; reg = <0x06280000 0x02000000>; };
            partition@8280000 {label = "rootfs0"; reg = <0x08280000 0x02000000>; };
            partition@A280000 {label = "rootfs1"; reg = <0x0A280000 0x02000000>; };
            partition@C280000 {label = "rootfs2"; reg = <0x0C280000 0x02000000>; };
            partition@E280000 {label = "appfs0"; reg = <0x0E280000 0x10000000>; };
            partition@1E280000 {label = "appfs1"; reg = <0x1E280000 0x10000000>; };
            partition@2E280000 {label = "appfs2"; reg = <0x2E280000 0x10000000>; };
        };
    };
    ems_flash_part {
        emspart = "ems-flash";
        partitions {
            compatible = "fixed-partitions";
            #address-cells = <1>;
            #size-cells = <1>;
            partition@0 {label = "loader0"; reg = <0x00000000 0x00400000>; };
            partition@400000 {label = "loader1"; reg = <0x00400000 0x00400000>; };
            partition@800000 {label = "ubootenv"; reg = <0x00800000 0x00080000>; bootable; };
            partition@880000 {label = "sysflag"; reg = <0x00880000 0x00080000>; bootable; };
            partition@900000 {label = "fdt0"; reg = <0x00900000 0x00080000>; };
            partition@980000 {label = "fdt1"; reg = <0x00980000 0x00080000>; };
            partition@A00000 {label = "fdt2"; reg = <0x00A00000 0x00080000>; };
            partition@A80000 {label = "teeos0"; reg = <0x00A80000 0x00400000>; };
            partition@E80000 {label = "teeos1"; reg = <0x00E80000 0x00400000>; };
            partition@1280000 {label = "teeos2"; reg = <0x01280000 0x00400000>; };
            partition@1680000 {label = "uboot0"; reg = <0x01680000 0x00400000>; };
            partition@1A80000 {label = "uboot1"; reg = <0x01A80000 0x00400000>; };
            partition@1E80000 {label = "uboot2"; reg = <0x01E80000 0x00400000>; };
            partition@2280000 {label = "kernel0"; reg = <0x02280000 0x02000000>; };
            partition@4280000 {label = "kernel1"; reg = <0x04280000 0x02000000>; };
            partition@6280000 {label = "kernel2"; reg = <0x06280000 0x02000000>; };
            partition@8280000 {label = "rootfs0"; reg = <0x08280000 0x02000000>; };
            partition@A280000 {label = "rootfs1"; reg = <0x0A280000 0x02000000>; };
            partition@C280000 {label = "rootfs2"; reg = <0x0C280000 0x02000000>; };
            partition@E280000 {label = "appfs0"; reg = <0x0E280000 0x10000000>; };
            partition@1E280000 {label = "appfs1"; reg = <0x1E280000 0x10000000>; };
            partition@2E280000 {label = "appfs2"; reg = <0x2E280000 0x10000000>; };
        };
    };
};
&main_pmx0 {
    gpio_custom_pins_default: gpio-custom-default-pins {
        pinctrl-single,pins = <
            (((0x0038) & 0x1fff)) ((((0 << (18)) | (1 << (16)))) | (7))
            (((0x0088) & 0x1fff)) ((((0 << (18)) | (1 << (16)))) | (7))
            (((0x0094) & 0x1fff)) ((((0 << (18)) | (1 << (16)))) | (7))
            (((0x009c) & 0x1fff)) ((((0 << (18)) | (1 << (16)))) | (7))
            (((0x00a0) & 0x1fff)) ((((0 << (18)) | (1 << (16)))) | (7))
            (((0x00ac) & 0x1fff)) ((((0 << (18)) | (1 << (16)))) | (7))
            (((0x00e4) & 0x1fff)) ((((0 << (18)) | (1 << (16)))) | (7))
            (((0x00e8) & 0x1fff)) ((((1 << (18)) | (1 << (14)) | (1 << (16)))) | (7))
            (((0x00ec) & 0x1fff)) ((((0 << (18)) | (1 << (16)))) | (7))
            (((0x00f0) & 0x1fff)) ((((0 << (18)) | (1 << (16)))) | (7))
            (((0x00f4) & 0x1fff)) ((((0 << (18)) | (1 << (16)))) | (7))
            (((0x00f8) & 0x1fff)) ((((0 << (18)) | (1 << (16)))) | (7))
        >;
    };
};
&pruss {
    status = "disabled";
};
&mcasp1 {
    status = "disabled";
};
&ecap0 {
    status = "disabled";
};
&main_rti15 {
    status = "disabled";
};
&main_rti3 {
    status = "disabled";
};
&main_rti2 {
    status = "disabled";
};
&main_rti1 {
    status = "disabled";
};
&main_rti0 {
    status = "okay";
};
&ecap2 {
    status = "disabled";
};
&epwm1 {
    status = "disabled";
};
&dss {
    status = "disabled";
};
&gpu {
    status = "disabled";
};
&usbss1 {
    status = "disabled";
};
&usbss0 {
    status = "disabled";
};
&wkup_vtm0 {
    status = "disabled";
};
&wkup_r5fss0 {
    status = "disabled";
};
&wkup_rtc0 {
    status = "disabled";
};
&ospi0 {
    status = "disabled";
};
&sii9022 {
    status = "disabled";
};
&tlv320aic3106 {
    status = "disabled";
};
&main_gpio0 {
    status = "okay";
    pinctrl-names = "default";
    pinctrl-0 = <&gpio_custom_pins_default>;
};
&main_gpio1 {
    status = "okay";
};
&sdhci1 {
    status = "okay";
    max-frequency = <25000000>;
    /delete-property/ vmmc-supply;
    /delete-property/ vqmmc-supply;
};
&reserved_memory {
 shmem_ems_sysflag: shmem_ems_sysflag@98000000 {
  compatible = "shmem_ems";
  reg = <0x0 0x98000000 0x0 0x400000>;
  no-map;
 };
};
